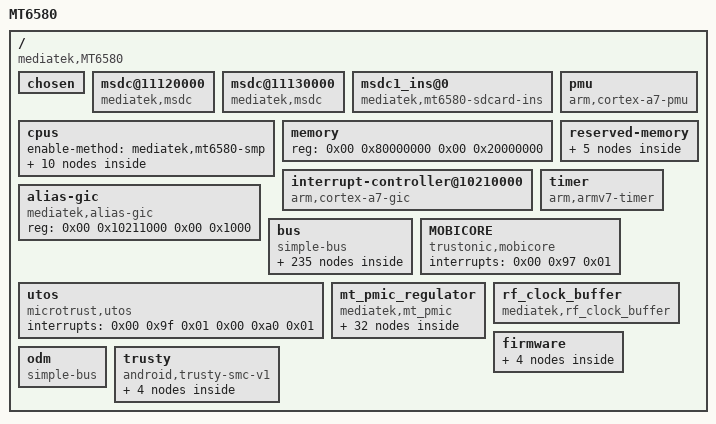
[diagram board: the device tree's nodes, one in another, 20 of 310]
/dts-v1/;

/ {
	model = "MT6580";
	compatible = "mediatek,MT6580";
	interrupt-parent = <0x01>;
	#address-cells = <0x02>;
	#size-cells = <0x02>;

	chosen {
		bootargs = "console=tty0 console=ttyMT3,921600n1 vmalloc=496M androidboot.hardware=mt6580 firmware_class.path=/vendor/firmware loop.max_part=7";
		linux,phandle = <0x2f>;
		phandle = <0x2f>;
	};

	msdc@11120000 {
		compatible = "mediatek,msdc";
		reg = <0x00 0x11120000 0x00 0x10000>;
		interrupts = <0x00 0x26 0x08>;
		index = [00];
		clk_src = [02];
		bus-width = <0x08>;
		max-frequency = <0xbebc200>;
		cap-mmc-highspeed;
		mmc-ddr-1_8v;
		mmc-hs200-1_8v;
		no-sd;
		no-sdio;
		non-removable;
		pinctl = <0x02>;
		pinctl_hs200 = <0x03>;
		register_setting = <0x04>;
		host_function = [00];
		bootable;
		status = "okay";
		vmmc-supply = <0x05>;
		linux,phandle = <0x30>;
		phandle = <0x30>;
	};

	msdc@11130000 {
		compatible = "mediatek,msdc";
		reg = <0x00 0x11130000 0x00 0x10000>;
		interrupts = <0x00 0x27 0x08>;
		index = [01];
		clk_src = [02];
		bus-width = <0x04>;
		max-frequency = <0xbebc200>;
		cap-sd-highspeed;
		sd-uhs-sdr12;
		sd-uhs-sdr25;
		sd-uhs-ddr50;
		no-mmc;
		no-sdio;
		pinctrl-names = "default\0insert_cfg";
		pinctrl-0 = <0x06>;
		pinctrl-1 = <0x07>;
		pinctl = <0x08>;
		pinctl_sdr104 = <0x09>;
		pinctl_sdr50 = <0x0a>;
		pinctl_ddr50 = <0x0b>;
		register_setting = <0x0c>;
		host_function = [01];
		cd_level = [01];
		cd-gpios = <0x0d 0x03 0x00>;
		status = "okay";
		vmmc-supply = <0x0e>;
		vqmmc-supply = <0x0f>;
		linux,phandle = <0x31>;
		phandle = <0x31>;
	};

	msdc1_ins@0 {
		compatible = "mediatek,mt6580-sdcard-ins";
		linux,phandle = <0x32>;
		phandle = <0x32>;
	};

	cpus {
		#address-cells = <0x01>;
		#size-cells = <0x00>;
		enable-method = "mediatek,mt6580-smp";

		cpu@0 {
			device_type = "cpu";
			compatible = "arm,cortex-a7";
			reg = <0x00>;
			clock-frequency = <0x6553f100>;
			linux,phandle = <0x10>;
			phandle = <0x10>;
		};

		cpu@1 {
			device_type = "cpu";
			compatible = "arm,cortex-a7";
			reg = <0x01>;
			clock-frequency = <0x6553f100>;
			linux,phandle = <0x11>;
			phandle = <0x11>;
		};

		cpu@2 {
			device_type = "cpu";
			compatible = "arm,cortex-a7";
			reg = <0x02>;
			clock-frequency = <0x6553f100>;
			linux,phandle = <0x12>;
			phandle = <0x12>;
		};

		cpu@3 {
			device_type = "cpu";
			compatible = "arm,cortex-a7";
			reg = <0x03>;
			clock-frequency = <0x6553f100>;
			linux,phandle = <0x13>;
			phandle = <0x13>;
		};

		cpu-map {

			cluster0 {

				core0 {
					cpu = <0x10>;
				};

				core1 {
					cpu = <0x11>;
				};

				core2 {
					cpu = <0x12>;
				};

				core3 {
					cpu = <0x13>;
				};
			};
		};
	};

	pmu {
		compatible = "arm,cortex-a7-pmu";
		interrupts = <0x00 0x04 0x08 0x00 0x05 0x08 0x00 0x06 0x08 0x00 0x07 0x08>;
	};

	memory {
		device_type = "memory";
		reg = <0x00 0x80000000 0x00 0x20000000>;
	};

	reserved-memory {
		#address-cells = <0x02>;
		#size-cells = <0x02>;
		ranges;
		linux,phandle = <0x33>;
		phandle = <0x33>;

		consys-reserve-memory {
			compatible = "mediatek,consys-reserve-memory";
			no-map;
			size = <0x00 0x200000>;
			alignment = <0x00 0x200000>;
		};

		reserve-memory-ccci_md1 {
			compatible = "mediatek,reserve-memory-ccci_md1";
			no-map;
			size = <0x00 0x1800000>;
			alignment = <0x00 0x2000000>;
			alloc-ranges = <0x00 0x80000000 0x00 0x80000000>;
		};

		pstore-reserved-memory@83f10000 {
			compatible = "mediatek,pstore";
			reg = <0x00 0x83f10000 0x00 0xe0000>;
		};

		ram_console-reserved-memory@83f00000 {
			compatible = "mediatek,ram_console";
			reg = <0x00 0x83f00000 0x00 0x10000>;
		};

		minirdump-reserved-memory@83ff0000 {
			compatible = "mediatek, minirdump";
			reg = <0x00 0x83ff0000 0x00 0x10000>;
		};
	};

	interrupt-controller@10210000 {
		compatible = "arm,cortex-a7-gic";
		#interrupt-cells = <0x03>;
		#address-cells = <0x00>;
		interrupt-controller;
		reg = <0x00 0x10211000 0x00 0x1000 0x00 0x10212000 0x00 0x1000 0x00 0x10200100 0x00 0x1000>;
		interrupts = <0x01 0x09 0xf04>;
		linux,phandle = <0x01>;
		phandle = <0x01>;
	};

	alias-gic {
		compatible = "mediatek,alias-gic";
		reg = <0x00 0x10211000 0x00 0x1000>;
	};

	timer {
		compatible = "arm,armv7-timer";
		interrupts = <0x01 0x0d 0x08 0x01 0x0e 0x08 0x01 0x0b 0x08 0x01 0x0a 0x08>;
		clock-frequency = <0xc65d40>;
	};

	bus {
		compatible = "simple-bus";
		#address-cells = <0x01>;
		#size-cells = <0x01>;
		ranges = <0x00 0x00 0x00 0xffffffff>;
		linux,phandle = <0x34>;
		phandle = <0x34>;

		chipid@08000000 {
			compatible = "mediatek,chipid";
			reg = <0x8000000 0x04 0x8000004 0x04 0x8000008 0x04 0x800000c 0x04>;
		};

		TOPCKGEN@0x10000000 {
			compatible = "mediatek,TOPCKGEN";
			reg = <0x10000000 0x1000>;
		};

		INFRACFG_AO@0x10001000 {
			compatible = "mediatek,INFRACFG_AO";
			reg = <0x10001000 0x1000>;
		};

		bat_meter {
			compatible = "mediatek,bat_meter";
			r_bat_sense = <0x04>;
			r_i_sense = <0x04>;
			r_charger_1 = <0x14a>;
			r_charger_2 = <0x27>;
			temperature_t0 = <0x6e>;
			temperature_t1 = <0x00>;
			temperature_t2 = <0x19>;
			temperature_t3 = <0x32>;
			temperature_t = <0xff>;
			fg_meter_resistance = <0x00>;
			q_max_pos_50 = <0xdd7>;
			q_max_pos_25 = <0xe11>;
			q_max_pos_0 = <0xe07>;
			q_max_neg_10 = <0xd86>;
			q_max_pos_50_h_current = <0xdbd>;
			q_max_pos_25_h_current = <0xde3>;
			q_max_pos_0_h_current = <0x968>;
			q_max_neg_10_h_current = <0x51f>;
			oam_d5 = <0x00>;
			change_tracking_point = <0x01>;
			cust_tracking_point = <0x00>;
			cust_r_sense = <0xc8>;
			cust_hw_cc = <0x00>;
			aging_tuning_value = <0x67>;
			cust_r_fg_offset = <0x00>;
			ocv_board_compesate = <0x00>;
			r_fg_board_base = <0x3e8>;
			r_fg_board_slope = <0x3e8>;
			car_tune_value = <0x64>;
			current_detect_r_fg = <0x0a>;
			minerroroffset = <0x3e8>;
			fg_vbat_average_size = <0x12>;
			r_fg_value = <0x0a>;
			cust_poweron_delta_capacity_tolrance = <0x3c>;
			cust_poweron_low_capacity_tolrance = <0x05>;
			cust_poweron_max_vbat_tolrance = <0x5a>;
			cust_poweron_delta_vbat_tolrance = <0x1e>;
			cust_poweron_delta_hw_sw_ocv_capacity_tolrance = <0x0a>;
			fixed_tbat_25 = <0x00>;
			vbat_normal_wakeup = <0xe10>;
			vbat_low_power_wakeup = <0xdac>;
			normal_wakeup_period = <0x1518>;
			low_power_wakeup_period = <0x12c>;
			close_poweroff_wakeup_period = <0x1e>;
			vbat_remove_detection = <0x00>;
			rbat_pull_up_r = <0x4204>;
			rbat_pull_up_volt = <0x708>;
			batt_temperature_table_num = <0x11>;
			batt_temperature_table = <0xffffffec 0x10a8d 0xfffffff1 0xd192 0xfffffff6 0xa60a 0xfffffffb 0x8464 0x00 0x6a53 0x05 0x5605 0x0a 0x4606 0x0f 0x3952 0x14 0x2f31 0x19 0x2710 0x1e 0x207b 0x23 0x1b24 0x28 0x16ca 0x2d 0x1335 0x32 0x1041 0x37 0xdcf 0x3c 0xbc6>;
			battery_profile_t0_num = <0x44>;
			battery_profile_t0 = <0x00 0x1125 0x02 0x110c 0x03 0x10f6 0x05 0x10df 0x06 0x10ca 0x08 0x10b6 0x09 0x10a3 0x0b 0x1091 0x0d 0x107f 0x0e 0x106e 0x10 0x105d 0x11 0x104c 0x13 0x103b 0x14 0x102a 0x16 0x1019 0x17 0x1008 0x19 0xff9 0x1b 0xfea 0x1c 0xfd9 0x1e 0xfc4 0x1f 0xfaa 0x21 0xf93 0x22 0xf80 0x24 0xf71 0x26 0xf64 0x27 0xf59 0x29 0xf4d 0x2a 0xf43 0x2c 0xf38 0x2d 0xf2e 0x2f 0xf24 0x30 0xf19 0x32 0xf10 0x34 0xf08 0x35 0xf00 0x37 0xef8 0x38 0xef1 0x3a 0xeea 0x3b 0xee4 0x3d 0xede 0x3f 0xed9 0x40 0xed5 0x42 0xed1 0x43 0xecd 0x45 0xeca 0x46 0xec7 0x48 0xec4 0x49 0xec0 0x4b 0xebc 0x4d 0xeb8 0x4e 0xeb4 0x50 0xeaf 0x51 0xeaa 0x53 0xea4 0x54 0xe9d 0x56 0xe95 0x58 0xe8d 0x59 0xe84 0x5b 0xe7d 0x5c 0xe77 0x5e 0xe71 0x5f 0xe6b 0x61 0xe5e 0x62 0xe39 0x64 0xdf3 0x64 0xdf3 0x64 0xdf3 0x64 0xdf3>;
			battery_profile_t1_num = <0x44>;
			battery_profile_t1 = <0x00 0x1125 0x02 0x110a 0x03 0x10f4 0x05 0x10e0 0x06 0x10cd 0x08 0x10b9 0x09 0x10a7 0x0b 0x1096 0x0c 0x1084 0x0e 0x1073 0x0f 0x1062 0x11 0x1051 0x12 0x1041 0x14 0x1031 0x15 0x1020 0x17 0x1010 0x18 0x1001 0x1a 0xff4 0x1b 0xfe7 0x1d 0xfd7 0x1e 0xfc0 0x20 0xfa8 0x21 0xf94 0x23 0xf85 0x24 0xf78 0x26 0xf6c 0x27 0xf60 0x29 0xf54 0x2a 0xf46 0x2c 0xf3a 0x2d 0xf2e 0x2f 0xf23 0x30 0xf19 0x32 0xf0f 0x33 0xf06 0x35 0xeff 0x36 0xef7 0x38 0xef0 0x39 0xeea 0x3b 0xee5 0x3c 0xede 0x3e 0xeda 0x3f 0xed5 0x41 0xed1 0x42 0xecd 0x44 0xecb 0x45 0xec8 0x47 0xec5 0x48 0xec3 0x4a 0xec0 0x4b 0xebc 0x4d 0xeb9 0x4e 0xeb4 0x50 0xeaf 0x51 0xea9 0x53 0xea1 0x54 0xe99 0x56 0xe90 0x57 0xe86 0x59 0xe7b 0x5a 0xe73 0x5c 0xe6f 0x5d 0xe6b 0x5f 0xe64 0x60 0xe47 0x62 0xdf9 0x63 0xd80 0x64 0xce5>;
			battery_profile_t2_num = <0x44>;
			battery_profile_t2 = <0x00 0x1125 0x02 0x110c 0x03 0x10f9 0x05 0x10e7 0x06 0x10d4 0x08 0x10c2 0x09 0x10b0 0x0b 0x109f 0x0c 0x108d 0x0e 0x107b 0x0f 0x106b 0x11 0x1059 0x12 0x1049 0x14 0x1038 0x15 0x1027 0x17 0x1017 0x18 0x1007 0x1a 0xff6 0x1b 0xfe7 0x1d 0xfdb 0x1e 0xfcc 0x20 0xfb8 0x21 0xfa7 0x23 0xf9a 0x24 0xf92 0x26 0xf86 0x27 0xf7a 0x29 0xf6d 0x2a 0xf5f 0x2c 0xf4f 0x2d 0xf3c 0x2f 0xf2d 0x30 0xf21 0x32 0xf17 0x33 0xf0e 0x35 0xf05 0x36 0xeff 0x38 0xef7 0x39 0xef1 0x3b 0xeea 0x3c 0xee5 0x3e 0xee0 0x3f 0xeda 0x41 0xed6 0x42 0xed2 0x44 0xecd 0x45 0xec9 0x47 0xec6 0x48 0xec1 0x4a 0xebb 0x4b 0xeb6 0x4d 0xeb1 0x4e 0xeaa 0x50 0xea4 0x51 0xe9f 0x53 0xe9a 0x54 0xe92 0x56 0xe88 0x57 0xe80 0x59 0xe74 0x5a 0xe6c 0x5c 0xe6a 0x5d 0xe69 0x5f 0xe66 0x60 0xe54 0x62 0xe14 0x63 0xdb0 0x64 0xcf7>;
			battery_profile_t3_num = <0x44>;
			battery_profile_t3 = <0x00 0x1113 0x02 0x10fe 0x03 0x10ea 0x05 0x10d8 0x06 0x10c7 0x08 0x10b4 0x09 0x10a3 0x0b 0x1092 0x0c 0x1080 0x0e 0x106f 0x0f 0x105e 0x11 0x104c 0x12 0x103c 0x14 0x102b 0x15 0x101b 0x17 0x100b 0x18 0xffb 0x1a 0xfeb 0x1b 0xfdc 0x1d 0xfcd 0x1f 0xfbf 0x20 0xfb1 0x22 0xfa4 0x23 0xf96 0x25 0xf8a 0x26 0xf7d 0x28 0xf71 0x29 0xf66 0x2b 0xf58 0x2c 0xf45 0x2e 0xf32 0x2f 0xf25 0x31 0xf1a 0x32 0xf10 0x34 0xf07 0x35 0xf00 0x37 0xef9 0x38 0xef2 0x3a 0xeeb 0x3c 0xee5 0x3d 0xee0 0x3f 0xeda 0x40 0xed5 0x42 0xed0 0x43 0xecc 0x45 0xec8 0x46 0xec3 0x48 0xebd 0x49 0xeb1 0x4b 0xea9 0x4c 0xea2 0x4e 0xe9c 0x4f 0xe95 0x51 0xe90 0x52 0xe8b 0x54 0xe83 0x56 0xe7a 0x57 0xe71 0x59 0xe66 0x5a 0xe5f 0x5c 0xe5e 0x5d 0xe5c 0x5f 0xe59 0x60 0xe43 0x62 0xe01 0x63 0xd9f 0x64 0xceb 0x64 0xc07>;
			r_profile_t0_num = <0x44>;
			r_profile_t0 = <0x514 0x1125 0x514 0x110c 0x4e9 0x10f6 0x4b5 0x10df 0x48a 0x10ca 0x463 0x10b6 0x440 0x10a3 0x423 0x1091 0x40b 0x107f 0x3f3 0x106e 0x3e0 0x105d 0x3d1 0x104c 0x3c4 0x103b 0x3b8 0x102a 0x3ab 0x1019 0x3a3 0x1008 0x39b 0xff9 0x399 0xfea 0x392 0xfd9 0x389 0xfc4 0x37f 0xfaa 0x379 0xf93 0x374 0xf80 0x37a 0xf71 0x37f 0xf64 0x382 0xf59 0x388 0xf4d 0x38d 0xf43 0x38c 0xf38 0x38e 0xf2e 0x38f 0xf24 0x392 0xf19 0x396 0xf10 0x399 0xf08 0x39c 0xf00 0x3a0 0xef8 0x3a1 0xef1 0x3a2 0xeea 0x3a6 0xee4 0x3a9 0xede 0x3ad 0xed9 0x3b2 0xed5 0x3b7 0xed1 0x3bd 0xecd 0x3c3 0xeca 0x3c9 0xec7 0x3d2 0xec4 0x3dc 0xec0 0x3e8 0xebc 0x3f4 0xeb8 0x3ff 0xeb4 0x40b 0xeaf 0x41a 0xeaa 0x426 0xea4 0x436 0xe9d 0x449 0xe95 0x459 0xe8d 0x46c 0xe84 0x485 0xe7d 0x49f 0xe77 0x4c3 0xe71 0x4f2 0xe6b 0x529 0xe5e 0x566 0xe39 0x7e4 0xdf3 0x7e4 0xdf3 0x7e4 0xdf3 0x7e4 0xdf3>;
			r_profile_t1_num = <0x44>;
			r_profile_t1 = <0x357 0x1125 0x357 0x110a 0x34b 0x10f4 0x33f 0x10e0 0x331 0x10cd 0x326 0x10b9 0x31b 0x10a7 0x30e 0x1096 0x301 0x1084 0x2f4 0x1073 0x2ea 0x1062 0x2df 0x1051 0x2d5 0x1041 0x2cd 0x1031 0x2c3 0x1020 0x2bc 0x1010 0x2b2 0x1001 0x2af 0xff4 0x2ac 0xfe7 0x2a5 0xfd7 0x297 0xfc0 0x28c 0xfa8 0x287 0xf94 0x286 0xf85 0x285 0xf78 0x284 0xf6c 0x281 0xf60 0x27c 0xf54 0x277 0xf46 0x274 0xf3a 0x270 0xf2e 0x26f 0xf23 0x270 0xf19 0x270 0xf0f 0x270 0xf06 0x271 0xeff 0x271 0xef7 0x272 0xef0 0x276 0xeea 0x279 0xee5 0x27e 0xede 0x284 0xeda 0x284 0xed5 0x284 0xed1 0x285 0xecd 0x288 0xecb 0x28c 0xec8 0x291 0xec5 0x29b 0xec3 0x2a4 0xec0 0x2ae 0xebc 0x2bb 0xeb9 0x2c8 0xeb4 0x2d6 0xeaf 0x2e7 0xea9 0x2fb 0xea1 0x311 0xe99 0x32a 0xe90 0x346 0xe86 0x365 0xe7b 0x387 0xe73 0x3b2 0xe6f 0x3e5 0xe6b 0x420 0xe64 0x456 0xe47 0x48d 0xdf9 0x447 0xd80 0x2d2 0xce5>;
			r_profile_t2_num = <0x44>;
			r_profile_t2 = <0xb8 0x1125 0xb8 0x110c 0xb8 0x10f9 0xba 0x10e7 0xba 0x10d4 0xb9 0x10c2 0xb7 0x10b0 0xb7 0x109f 0xb7 0x108d 0xb9 0x107b 0xb8 0x106b 0xb6 0x1059 0xb7 0x1049 0xb8 0x1038 0xb6 0x1027 0xb8 0x1017 0xb9 0x1007 0xb8 0xff6 0xbb 0xfe7 0xc1 0xfdb 0xc1 0xfcc 0xc0 0xfb8 0xc0 0xfa7 0xbe 0xf9a 0xca 0xf92 0xc7 0xf86 0xc6 0xf7a 0xc2 0xf6d 0xc3 0xf5f 0xbf 0xf4f 0xb3 0xf3c 0xad 0xf2d 0xa9 0xf21 0xa6 0xf17 0xaa 0xf0e 0xab 0xf05 0xab 0xeff 0xa8 0xef7 0xaa 0xef1 0xab 0xeea 0xaf 0xee5 0xb0 0xee0 0xaf 0xeda 0xb1 0xed6 0xb2 0xed2 0xb4 0xecd 0xb6 0xec9 0xb5 0xec6 0xb8 0xec1 0xb4 0xebb 0xb3 0xeb6 0xb4 0xeb1 0xb1 0xeaa 0xb2 0xea4 0xb1 0xe9f 0xb4 0xe9a 0xb5 0xe92 0xb6 0xe88 0xb7 0xe80 0xb9 0xe74 0xb8 0xe6c 0xbc 0xe6a 0xc2 0xe69 0xcd 0xe66 0xd4 0xe54 0xd3 0xe14 0xe3 0xdb0 0x111 0xcf7>;
			r_profile_t3_num = <0x44>;
			r_profile_t3 = <0x80 0x1113 0x80 0x10fe 0x7e 0x10ea 0x7f 0x10d8 0x7f 0x10c7 0x7d 0x10b4 0x7f 0x10a3 0x7f 0x1092 0x7e 0x1080 0x7f 0x106f 0x80 0x105e 0x7f 0x104c 0x7f 0x103c 0x81 0x102b 0x81 0x101b 0x81 0x100b 0x83 0xffb 0x83 0xfeb 0x83 0xfdc 0x85 0xfcd 0x86 0xfbf 0x86 0xfb1 0x88 0xfa4 0x89 0xf96 0x8d 0xf8a 0x8e 0xf7d 0x90 0xf71 0x94 0xf66 0x94 0xf58 0x8a 0xf45 0x81 0xf32 0x80 0xf25 0x7e 0xf1a 0x7d 0xf10 0x7c 0xf07 0x7d 0xf00 0x7d 0xef9 0x7e 0xef2 0x7f 0xeeb 0x80 0xee5 0x81 0xee0 0x81 0xeda 0x82 0xed5 0x83 0xed0 0x84 0xecc 0x85 0xec8 0x87 0xec3 0x85 0xebd 0x7e 0xeb1 0x7d 0xea9 0x7e 0xea2 0x7d 0xe9c 0x7d 0xe95 0x7d 0xe90 0x7f 0xe8b 0x80 0xe83 0x7f 0xe7a 0x80 0xe71 0x7f 0xe66 0x7c 0xe5f 0x7f 0xe5e 0x83 0xe5c 0x8c 0xe59 0x88 0xe43 0x85 0xe01 0x8f 0xd9f 0xab 0xceb 0x188 0xc07>;
		};

		bat_meter1 {
			compatible = "mediatek,bat_meter1";
			r_bat_sense = <0x04>;
			r_i_sense = <0x04>;
			r_charger_1 = <0x14a>;
			r_charger_2 = <0x27>;
			temperature_t0 = <0x6e>;
			temperature_t1 = <0x00>;
			temperature_t2 = <0x19>;
			temperature_t3 = <0x32>;
			temperature_t = <0xff>;
			fg_meter_resistance = <0x00>;
			q_max_pos_50 = <0xd87>;
			q_max_pos_25 = <0xdbb>;
			q_max_pos_0 = <0xdab>;
			q_max_neg_10 = <0xd94>;
			q_max_pos_50_h_current = <0xd6b>;
			q_max_pos_25_h_current = <0xd7c>;
			q_max_pos_0_h_current = <0x99d>;
			q_max_neg_10_h_current = <0x55a>;
			oam_d5 = <0x00>;
			change_tracking_point = <0x01>;
			cust_tracking_point = <0x00>;
			cust_r_sense = <0xc8>;
			cust_hw_cc = <0x00>;
			aging_tuning_value = <0x67>;
			cust_r_fg_offset = <0x00>;
			ocv_board_compesate = <0x00>;
			r_fg_board_base = <0x3e8>;
			r_fg_board_slope = <0x3e8>;
			car_tune_value = <0x64>;
			current_detect_r_fg = <0x0a>;
			minerroroffset = <0x3e8>;
			fg_vbat_average_size = <0x12>;
			r_fg_value = <0x0a>;
			cust_poweron_delta_capacity_tolrance = <0x3c>;
			cust_poweron_low_capacity_tolrance = <0x05>;
			cust_poweron_max_vbat_tolrance = <0x5a>;
			cust_poweron_delta_vbat_tolrance = <0x1e>;
			cust_poweron_delta_hw_sw_ocv_capacity_tolrance = <0x0a>;
			fixed_tbat_25 = <0x00>;
			vbat_normal_wakeup = <0xe10>;
			vbat_low_power_wakeup = <0xdac>;
			normal_wakeup_period = <0x1518>;
			low_power_wakeup_period = <0x12c>;
			close_poweroff_wakeup_period = <0x1e>;
			vbat_remove_detection = <0x00>;
			rbat_pull_up_r = <0x4204>;
			rbat_pull_up_volt = <0x708>;
			batt_temperature_table_num = <0x11>;
			batt_temperature_table = <0xffffffec 0x10a8d 0xfffffff1 0xd192 0xfffffff6 0xa60a 0xfffffffb 0x8464 0x00 0x6a53 0x05 0x5605 0x0a 0x4606 0x0f 0x3952 0x14 0x2f31 0x19 0x2710 0x1e 0x207b 0x23 0x1b24 0x28 0x16ca 0x2d 0x1335 0x32 0x1041 0x37 0xdcf 0x3c 0xbc6>;
			battery_profile_t0_num = <0x64>;
			battery_profile_t0 = <0x00 0x1121 0x02 0x10f8 0x03 0x10d8 0x05 0x10bc 0x06 0x10a4 0x08 0x108d 0x09 0x1079 0x0b 0x1066 0x0c 0x1054 0x0e 0x1042 0x10 0x1031 0x11 0x1020 0x13 0x1010 0x14 0x1002 0x16 0xff2 0x17 0xfe0 0x19 0xfcc 0x1a 0xfb8 0x1c 0xfa5 0x1e 0xf94 0x1f 0xf85 0x21 0xf77 0x22 0xf6a 0x24 0xf5d 0x25 0xf51 0x27 0xf44 0x28 0xf38 0x2a 0xf2d 0x2b 0xf22 0x2d 0xf18 0x2f 0xf0f 0x30 0xf06 0x32 0xefe 0x33 0xef6 0x35 0xeef 0x36 0xee8 0x38 0xee3 0x39 0xede 0x3b 0xeda 0x3d 0xed6 0x3e 0xed2 0x40 0xecf 0x41 0xecc 0x43 0xec9 0x44 0xec6 0x46 0xec2 0x47 0xebf 0x49 0xebb 0x4b 0xeb8 0x4c 0xeb4 0x4e 0xeaf 0x4f 0xeaa 0x51 0xea5 0x52 0xe9f 0x54 0xe98 0x55 0xe91 0x57 0xe89 0x59 0xe80 0x5a 0xe78 0x5c 0xe71 0x5d 0xe6b 0x5f 0xe64 0x60 0xe5c 0x61 0xe55 0x62 0xe4c 0x62 0xe42 0x62 0xe35 0x63 0xe29 0x63 0xe1c 0x63 0xe10 0x64 0xe04 0x64 0xdf8 0x64 0xded 0x64 0xde3 0x64 0xdd9 0x64 0xdce 0x64 0xdc4 0x64 0xdbb 0x64 0xdb2 0x64 0xdaa 0x64 0xda1 0x64 0xd9a 0x64 0xd92 0x64 0xd8b 0x64 0xd84 0x64 0xd7d 0x64 0xd77 0x64 0xd70 0x64 0xd6a 0x64 0xd65 0x64 0xd5f 0x64 0xd5a 0x64 0xd54 0x64 0xd50 0x64 0xd4c 0x64 0xd48 0x64 0xd48 0x64 0xd48 0x64 0xd48 0x64 0xd48>;
			battery_profile_t1_num = <0x4a>;
			battery_profile_t1 = <0x00 0x1119 0x02 0x10f9 0x03 0x10e0 0x05 0x10c9 0x06 0x10b4 0x08 0x10a0 0x09 0x108d 0x0b 0x107b 0x0c 0x1069 0x0e 0x1058 0x0f 0x1046 0x11 0x1035 0x13 0x1024 0x14 0x1014 0x16 0x1004 0x17 0xff6 0x19 0xfe7 0x1a 0xfd6 0x1c 0xfc2 0x1d 0xfad 0x1f 0xf9b 0x20 0xf8c 0x22 0xf7e 0x23 0xf71 0x25 0xf65 0x27 0xf58 0x28 0xf4b 0x2a 0xf3d 0x2b 0xf30 0x2d 0xf24 0x2e 0xf19 0x30 0xf0f 0x31 0xf06 0x33 0xefe 0x34 0xef6 0x36 0xeef 0x38 0xee9 0x39 0xee3 0x3b 0xedd 0x3c 0xed8 0x3e 0xed4 0x3f 0xed1 0x41 0xece 0x42 0xecc 0x44 0xec9 0x45 0xec6 0x47 0xec3 0x49 0xec0 0x4a 0xebd 0x4c 0xeb9 0x4d 0xeb4 0x4f 0xeaf 0x50 0xea9 0x52 0xea2 0x53 0xe9b 0x55 0xe92 0x56 0xe88 0x58 0xe7e 0x59 0xe74 0x5b 0xe6e 0x5d 0xe69 0x5e 0xe64 0x60 0xe54 0x61 0xe20 0x62 0xde2 0x63 0xdba 0x63 0xd97 0x64 0xd77 0x64 0xd57 0x64 0xd48 0x64 0xd48 0x64 0xd48 0x64 0xd48 0x64 0xd48>;
			battery_profile_t2_num = <0x46>;
			battery_profile_t2 = <0x00 0x111f 0x02 0x1107 0x03 0x10f4 0x05 0x10e1 0x06 0x10ce 0x08 0x10bc 0x09 0x10aa 0x0b 0x1097 0x0c 0x1085 0x0e 0x1073 0x0f 0x1062 0x11 0x1050 0x12 0x103f 0x14 0x102e 0x16 0x101d 0x17 0x100c 0x19 0xffc 0x1a 0xfed 0x1c 0xfde 0x1d 0xfcf 0x1f 0xfbe 0x20 0xfae 0x22 0xfa0 0x23 0xf94 0x25 0xf88 0x26 0xf7c 0x28 0xf6f 0x29 0xf60 0x2b 0xf4e 0x2d 0xf3d 0x2e 0xf2e 0x30 0xf21 0x31 0xf17 0x33 0xf0e 0x34 0xf06 0x36 0xefe 0x37 0xef7 0x39 0xef0 0x3a 0xeea 0x3c 0xee4 0x3d 0xedf 0x3f 0xeda 0x41 0xed5 0x42 0xed1 0x44 0xecd 0x45 0xec9 0x47 0xec4 0x48 0xec0 0x4a 0xeba 0x4b 0xeb4 0x4d 0xeae 0x4e 0xea8 0x50 0xea3 0x51 0xe9e 0x53 0xe97 0x54 0xe8e 0x56 0xe86 0x58 0xe7c 0x59 0xe70 0x5b 0xe6b 0x5c 0xe69 0x5e 0xe66 0x5f 0xe5f 0x61 0xe37 0x62 0xde7 0x64 0xd67 0x64 0xd48 0x64 0xd48 0x64 0xd48 0x64 0xd48>;
			battery_profile_t3_num = <0x45>;
			battery_profile_t3 = <0x00 0x110c 0x02 0x10f5 0x03 0x10e0 0x05 0x10cd 0x06 0x10ba 0x08 0x10a8 0x09 0x1095 0x0b 0x1083 0x0c 0x1072 0x0e 0x1060 0x10 0x104e 0x11 0x103d 0x13 0x102c 0x14 0x101c 0x16 0x100b 0x17 0xffb 0x19 0xfeb 0x1b 0xfdc 0x1c 0xfcd 0x1e 0xfbf 0x1f 0xfb0 0x21 0xfa3 0x22 0xf96 0x24 0xf89 0x25 0xf7d 0x27 0xf71 0x29 0xf65 0x2a 0xf57 0x2c 0xf45 0x2d 0xf32 0x2f 0xf24 0x30 0xf1a 0x32 0xf10 0x33 0xf08 0x35 0xf00 0x37 0xef8 0x38 0xef2 0x3a 0xeeb 0x3b 0xee5 0x3d 0xedf 0x3e 0xeda 0x40 0xed5 0x41 0xed1 0x43 0xecd 0x45 0xec9 0x46 0xec4 0x48 0xebd 0x49 0xeb1 0x4b 0xea9 0x4c 0xea3 0x4e 0xe9c 0x50 0xe96 0x51 0xe91 0x53 0xe8b 0x54 0xe83 0x56 0xe7a 0x57 0xe71 0x59 0xe65 0x5a 0xe60 0x5c 0xe5f 0x5e 0xe5d 0x5f 0xe56 0x61 0xe2e 0x62 0xde2 0x64 0xd6b 0x64 0xd48 0x64 0xd48 0x64 0xd48 0x64 0xd48>;
			r_profile_t0_num = <0x63>;
			r_profile_t0 = <0x512 0x10f8 0x4df 0x10d8 0x4a8 0x10bc 0x47b 0x10a4 0x453 0x108d 0x433 0x1079 0x417 0x1066 0x3ff 0x1054 0x3ea 0x1042 0x3d7 0x1031 0x3c5 0x1020 0x3b1 0x1010 0x3a9 0x1002 0x39d 0xff2 0x390 0xfe0 0x386 0xfcc 0x373 0xfb8 0x364 0xfa5 0x357 0xf94 0x355 0xf85 0x34f 0xf77 0x350 0xf6a 0x34d 0xf5d 0x348 0xf51 0x34a 0xf44 0x343 0xf38 0x343 0xf2d 0x33e 0xf22 0x343 0xf18 0x346 0xf0f 0x345 0xf06 0x33b 0xefe 0x340 0xef6 0x348 0xeef 0x345 0xee8 0x348 0xee3 0x354 0xede 0x35c 0xeda 0x35f 0xed6 0x36b 0xed2 0x372 0xecf 0x378 0xecc 0x389 0xec9 0x390 0xec6 0x3a5 0xec2 0x3af 0xebf 0x3c8 0xebb 0x3d9 0xeb8 0x3ed 0xeb4 0x3fe 0xeaf 0x412 0xeaa 0x429 0xea5 0x43b 0xe9f 0x44e 0xe98 0x463 0xe91 0x47e 0xe89 0x492 0xe80 0x4b3 0xe78 0x4ce 0xe71 0x500 0xe6b 0x52f 0xe64 0x561 0xe5c 0x555 0xe55 0x546 0xe4c 0x535 0xe42 0x520 0xe35 0x50c 0xe29 0x4f6 0xe1c 0x4e2 0xe10 0x4ce 0xe04 0x4ba 0xdf8 0x4a8 0xded 0x497 0xde3 0x486 0xdd9 0x476 0xdce 0x465 0xdc4 0x456 0xdbb 0x447 0xdb2 0x438 0xdaa 0x42b 0xda1 0x41d 0xd9a 0x412 0xd92 0x404 0xd8b 0x3fa 0xd84 0x3ef 0xd7d 0x3e3 0xd77 0x3d9 0xd70 0x3cf 0xd6a 0x3c5 0xd65 0x3bb 0xd5f 0x3b4 0xd5a 0x3aa 0xd54 0x3a2 0xd50 0x39b 0xd4c 0x393 0xd48 0x38e 0xd48 0x38e 0xd48 0x38e 0xd48 0x38e 0xd48>;
			r_profile_t1_num = <0x49>;
			r_profile_t1 = <0x305 0x10f9 0x2ff 0x10e0 0x2f3 0x10c9 0x2e9 0x10b4 0x2da 0x10a0 0x2c9 0x108d 0x2a3 0x107b 0x299 0x1069 0x28a 0x1058 0x2a5 0x1046 0x299 0x1035 0x28f 0x1024 0x288 0x1014 0x283 0x1004 0x280 0xff6 0x280 0xfe7 0x279 0xfd6 0x26f 0xfc2 0x25d 0xfad 0x255 0xf9b 0x253 0xf8c 0x256 0xf7e 0x258 0xf71 0x256 0xf65 0x232 0xf58 0x229 0xf4b 0x228 0xf3d 0x242 0xf30 0x23f 0xf24 0x23d 0xf19 0x238 0xf0f 0x23d 0xf06 0x241 0xefe 0x23f 0xef6 0x23f 0xeef 0x242 0xee9 0x249 0xee3 0x249 0xedd 0x247 0xed8 0x249 0xed4 0x24e 0xed1 0x246 0xece 0x24c 0xecc 0x250 0xec9 0x27b 0xec6 0x291 0xec3 0x29e 0xec0 0x2a8 0xebd 0x2b4 0xeb9 0x2c3 0xeb4 0x2d8 0xeaf 0x2f0 0xea9 0x304 0xea2 0x313 0xe9b 0x32a 0xe92 0x348 0xe88 0x372 0xe7e 0x393 0xe74 0x3b6 0xe6e 0x3bd 0xe69 0x3ea 0xe64 0x410 0xe54 0x474 0xe20 0x495 0xde2 0x453 0xdba 0x418 0xd97 0x3e3 0xd77 0x3ae 0xd57 0x3ae 0xd48 0x3ae 0xd48 0x3ae 0xd48 0x3ae 0xd48 0x3ae 0xd48>;
			r_profile_t2_num = <0x45>;
			r_profile_t2 = <0xbc 0x1107 0xbe 0x10f4 0xbe 0x10e1 0xbc 0x10ce 0xbb 0x10bc 0xbb 0x10aa 0xb6 0x1097 0xb6 0x1085 0xb4 0x1073 0xb6 0x1062 0xb4 0x1050 0xb4 0x103f 0xb2 0x102e 0xb2 0x101d 0xb1 0x100c 0xb4 0xffc 0xb6 0xfed 0xb4 0xfde 0xb4 0xfcf 0xb2 0xfbe 0xb4 0xfae 0xb6 0xfa0 0xb9 0xf94 0xb9 0xf88 0xbb 0xf7c 0xbb 0xf6f 0xb7 0xf60 0xaf 0xf4e 0xa7 0xf3d 0xa0 0xf2e 0x9d 0xf21 0x9e 0xf17 0x9e 0xf0e 0xa0 0xf06 0x9e 0xefe 0xa0 0xef7 0xa0 0xef0 0xa2 0xeea 0xa3 0xee4 0xa5 0xedf 0xa5 0xeda 0xa7 0xed5 0xa8 0xed1 0xaa 0xecd 0xaa 0xec9 0xa8 0xec4 0xaa 0xec0 0xa7 0xeba 0xa5 0xeb4 0xa5 0xeae 0xa5 0xea8 0xa8 0xea3 0xac 0xe9e 0xad 0xe97 0xaf 0xe8e 0xb4 0xe86 0xb9 0xe7c 0xbc 0xe70 0xc3 0xe6b 0xcd 0xe69 0xdc 0xe66 0xee 0xe5f 0xfa 0xe37 0x115 0xde7 0x145 0xd67 0x145 0xd48 0x145 0xd48 0x145 0xd48 0x145 0xd48>;
			r_profile_t3_num = <0x44>;
			r_profile_t3 = <0x71 0x10f5 0x70 0x10e0 0x70 0x10cd 0x70 0x10ba 0x70 0x10a8 0x6e 0x1095 0x70 0x1083 0x70 0x1072 0x70 0x1060 0x70 0x104e 0x70 0x103d 0x70 0x102c 0x71 0x101c 0x71 0x100b 0x73 0xffb 0x73 0xfeb 0x75 0xfdc 0x75 0xfcd 0x76 0xfbf 0x76 0xfb0 0x78 0xfa3 0x7a 0xf96 0x7b 0xf89 0x7f 0xf7d 0x80 0xf71 0x82 0xf65 0x82 0xf57 0x7b 0xf45 0x71 0xf32 0x6e 0xf24 0x70 0xf1a 0x6e 0xf10 0x6e 0xf08 0x6e 0xf00 0x6e 0xef8 0x71 0xef2 0x70 0xeeb 0x71 0xee5 0x71 0xedf 0x73 0xeda 0x75 0xed5 0x76 0xed1 0x78 0xecd 0x7a 0xec9 0x7a 0xec4 0x76 0xebd 0x70 0xeb1 0x70 0xea9 0x71 0xea3 0x71 0xe9c 0x71 0xe96 0x73 0xe91 0x73 0xe8b 0x73 0xe83 0x73 0xe7a 0x73 0xe71 0x70 0xe65 0x70 0xe60 0x75 0xe5f 0x7a 0xe5d 0x80 0xe56 0x7a 0xe2e 0x7f 0xde2 0x8a 0xd6b 0x8a 0xd48 0x8a 0xd48 0x8a 0xd48 0x8a 0xd48>;
		};

		BAT_NOTIFY {
			compatible = "mediatek,bat_notify";
		};

		bat_comm {
			compatible = "mediatek,battery";
			linux,phandle = <0x35>;
			phandle = <0x35>;
		};

		keypad@10002000 {
			compatible = "mediatek,kp";
			reg = <0x10002000 0x1000>;
			interrupts = <0x00 0x6d 0x02>;
			linux,phandle = <0x36>;
			phandle = <0x36>;
		};

		PERICFG@0x10003000 {
			compatible = "mediatek,PERICFG";
			reg = <0x10003000 0x1000>;
		};

		RESERVED@0x10004000 {
			compatible = "mediatek,RESERVED";
			reg = <0x10004000 0x1000>;
		};

		gpio {
			compatible = "mediatek,gpio_usage_mapping";
			linux,phandle = <0x37>;
			phandle = <0x37>;
		};

		gpio@0x10005000 {
			compatible = "mediatek,gpio";
			reg = <0x10005000 0x1000>;
			linux,phandle = <0x38>;
			phandle = <0x38>;
		};

		SLEEP@0x10006000 {
			compatible = "mediatek,SLEEP";
			reg = <0x10006000 0x1000>;
			interrupts = <0x00 0x58 0x08 0x00 0x59 0x08 0x00 0x5a 0x08 0x00 0x5b 0x08>;
		};

		TOPRGU@0x10007000 {
			compatible = "mediatek,TOPRGU";
			reg = <0x10007000 0x1000>;
			interrupts = <0x00 0x9d 0x02>;
		};

		APXGPT@0x10008000 {
			compatible = "mediatek,APXGPT";
			reg = <0x10008000 0x1000>;
			interrupts = <0x00 0x5c 0x08>;
			clock-frequency = <0xc65d40>;
		};

		EFUSEC@0x10009000 {
			compatible = "mediatek,EFUSEC";
			reg = <0x10009000 0x1000>;
		};

		hacc@0x1000A000 {
			compatible = "mediatek,hacc";
			reg = <0x1000a000 0x1000>;
			interrupts = <0x00 0x6e 0x00>;
		};

		cpu_dbgapb@10170000 {
			compatible = "mediatek,hw_dbg";
			num = <0x04>;
			reg = <0x10170000 0x2000 0x10172000 0x2000 0x10174000 0x2000 0x10176000 0x2000>;
			linux,phandle = <0x39>;
			phandle = <0x39>;
		};

		eintc@1000b000 {
			compatible = "mediatek,mt-eic";
			reg = <0x1000b000 0x1000>;
			interrupts = <0x00 0x5e 0x04>;
			#interrupt-cells = <0x02>;
			interrupt-controller;
			mediatek,max_eint_num = <0x1a>;
			mediatek,mapping_table_entry = <0x53>;
			mediatek,mapping_table = <0x00 0x00 0x01 0x01 0x02 0x02 0x03 0x03 0x04 0x04 0x05 0x05 0x06 0x06 0x07 0x07 0x08 0x08 0x09 0x09 0x0a 0x0a 0x0b 0x0b 0x0c 0x0c 0x0d 0x0d 0x0e 0x0e 0x0f 0x0f 0x10 0x00 0x11 0x01 0x12 0x02 0x13 0x03 0x14 0x04 0x15 0x05 0x16 0x06 0x17 0x07 0x18 0x08 0x19 0x09 0x1a 0x0a 0x1b 0x0b 0x1c 0x0c 0x1d 0x0d 0x1e 0x0e 0x1f 0x0f 0x20 0x00 0x21 0x01 0x22 0x02 0x23 0x03 0x24 0x04 0x25 0x05 0x26 0x06 0x27 0x07 0x28 0x08 0x29 0x09 0x2a 0x0a 0x2b 0x0b 0x2c 0x0c 0x2d 0x0d 0x2e 0x0e 0x2f 0x0f 0x30 0x00 0x31 0x01 0x32 0x02 0x33 0x03 0x34 0x03 0x35 0x04 0x36 0x05 0x37 0x06 0x38 0x07 0x39 0x08 0x3a 0x0a 0x3b 0x0b 0x3c 0x0c 0x3d 0x0d 0x3e 0x0e 0x3f 0x0f 0x40 0x00 0x41 0x01 0x42 0x02 0x43 0x03 0x44 0x10 0x45 0x04 0x46 0x05 0x47 0x06 0x48 0x07 0x49 0x08 0x4a 0x09 0x4b 0x0a 0x4c 0x0b 0x4d 0x0c 0x4e 0x0d 0x51 0x00 0x52 0x01 0x53 0x02 0x54 0x03>;
			mediatek,builtin_entry = <0x0b>;
			mediatek,builtin_mapping = <0x00 0x03 0x14 0x01 0x03 0x12 0x07 0x04 0x14 0x08 0x04 0x12 0x09 0x03 0x14 0x0a 0x03 0x12 0x18 0x05 0x14 0x19 0x05 0x12 0x4d 0x02 0x14 0x4e 0x02 0x12 0x0d 0x01 0x11>;
			linux,phandle = <0x14>;
			phandle = <0x14>;

			pmic@13 {
				compatible = "mediatek, pmic-eint";
				interrupt-parent = <0x14>;
				interrupts = <0x0d 0x04>;
				debounce = <0x0d 0x3e8>;
			};
		};

		ap_ccif0@1000C000 {
			compatible = "mediatek,ap_ccif0";
			reg = <0x1000c000 0x1000 0x1000d000 0x1000>;
			interrupts = <0x00 0x5d 0x08 0x00 0x98 0x02>;
			mediatek,ccif_capability = <0x02>;
			mediatek,md_smem_size = <0x200000>;
			linux,phandle = <0x3a>;
			phandle = <0x3a>;
		};

		MCUSYS_CFGREG@0x1020000 {
			compatible = "mediatek,MCUSYS_CFGREG_BASE";
			reg = <0x1020000 0x200>;
		};

		mcucfg@10200000 {
			compatible = "mediatek,mt6580-mcucfg";
			reg = <0x10200000 0x200>;
			linux,phandle = <0x3b>;
			phandle = <0x3b>;
		};

		AES@0x1000E000 {
			compatible = "mediatek,AES";
			reg = <0x1000e000 0x1000>;
		};

		PWRAP@0x1000F000 {
			compatible = "mediatek,PWRAP";
			reg = <0x1000f000 0x1000>;
			interrupts = <0x00 0x6c 0x00>;
		};

		DEVAPC_AO@0x10010000 {
			compatible = "mediatek,DEVAPC_AO";
			reg = <0x10010000 0x1000>;
		};

		MIPI_CONFG@0x10011000 {
			compatible = "mediatek,MIPI_CONFG";
			reg = <0x10011000 0x1000>;
		};

		INFRA_MBIST@0x10012000 {
			compatible = "mediatek,INFRA_MBIST";
			reg = <0x10012000 0x1000>;
		};

		RESERVED@0x10013000 {
			compatible = "mediatek,RESERVED";
			reg = <0x10013000 0x1000>;
		};

		IOCFG_T@0x10014000 {
			compatible = "mediatek,IOCFG_T";
			reg = <0x10014000 0x1000>;
		};

		IOCFG_B@0x10015000 {
			compatible = "mediatek,IOCFG_B";
			reg = <0x10015000 0x1000>;
		};

		IOCFG_L@0x10016000 {
			compatible = "mediatek,IOCFG_L";
			reg = <0x10016000 0x1000>;
		};

		IOCFG_R@0x10017000 {
			compatible = "mediatek,IOCFG_R";
			reg = <0x10017000 0x1000>;
		};

		APMIXED@0x10018000 {
			compatible = "mediatek,APMIXED";
			reg = <0x10018000 0x1000>;
		};

		MCUCFG@0x10200000 {
			compatible = "mediatek,MCUCFG";
			reg = <0x10200000 0x1000>;
		};

		INFRACFG@0x10201000 {
			compatible = "mediatek,INFRACFG";
			reg = <0x10201000 0x1000>;
		};

		sys_cirq@10202000 {
			compatible = "mediatek,mt6580-sys_cirq\0mediatek,mt6735-sys_cirq";
			reg = <0x10202000 0x1000>;
			interrupts = <0x00 0x9e 0x08>;
			mediatek,cirq_num = <0x7e>;
			mediatek,spi_start_offset = <0x20>;
			linux,phandle = <0x3c>;
			phandle = <0x3c>;
		};

		m4u@10203000 {
			cell-index = <0x00>;
			compatible = "mediatek,m4u";
			reg = <0x10203000 0x1000>;
			interrupts = <0x00 0x51 0x08>;
		};

		DEVAPC@0x10204000 {
			compatible = "mediatek,DEVAPC";
			reg = <0x10204000 0x1000>;
			interrupts = <0x00 0x4a 0x08>;
		};

		EMI@0x10205000 {
			compatible = "mediatek,EMI";
			reg = <0x10205000 0x1000>;
			interrupts = <0x00 0x4c 0x04>;
		};

		DRAMC_NAO@0x10206000 {
			compatible = "mediatek,DRAMC_NAO";
			reg = <0x10206000 0x1000>;
		};

		DRAMC0@0x10207000 {
			compatible = "mediatek,DRAMC0";
			reg = <0x10207000 0x1000>;
		};

		DDRPHY@0x10208000 {
			compatible = "mediatek,DDRPHY";
			reg = <0x10208000 0x1000>;
		};

		SRAMROM@0x10209000 {
			compatible = "mediatek,SRAMROM";
			reg = <0x10209000 0x1000>;
		};

		gce@1020a000 {
			compatible = "mediatek,gce";
			reg = <0x1020a000 0x1000>;
			interrupts = <0x00 0x55 0x08 0x00 0x56 0x08>;
			disp_mutex_reg = <0x14015000 0x1000>;
			g3d_config_base = <0x13000000 0x00 0xffff0000>;
			mmsys_config_base = <0x14000000 0x01 0xffff0000>;
			disp_dither_base = <0x14010000 0x02 0xffff0000>;
			mm_na_base = <0x14020000 0x03 0xffff0000>;
			imgsys_base = <0x15000000 0x04 0xffff0000>;
			vdec_gcon_base = <0x16000000 0x05 0xffff0000>;
			venc_gcon_base = <0x17000000 0x06 0xffff0000>;
			conn_peri_base = <0x18000000 0x07 0xffff0000>;
			topckgen_base = <0x10000000 0x08 0xffff0000>;
			kp_base = <0x10010000 0x09 0xffff0000>;
			scp_sram_base = <0x10020000 0x0a 0xffff0000>;
			infra_na3_base = <0x10030000 0x0b 0xffff0000>;
			infra_na4_base = <0x10040000 0x0c 0xffff0000>;
			scp_base = <0x10050000 0x0d 0xffff0000>;
			mcucfg_base = <0x10200000 0x0e 0xffff0000>;
			gcpu_base = <0x10210000 0x0f 0xffff0000>;
			usb0_base = <0x11200000 0x10 0xffff0000>;
			usb_sif_base = <0x11210000 0x11 0xffff0000>;
			audio_base = <0x11220000 0x12 0xffff0000>;
			msdc0_base = <0x11230000 0x13 0xffff0000>;
			msdc1_base = <0x11240000 0x14 0xffff0000>;
			msdc2_base = <0x11250000 0x15 0xffff0000>;
			msdc3_base = <0x11260000 0x16 0xffff0000>;
			pwm_sw_base = <0x1100f000 0x63 0xfffff000>;
			mdp_rdma0_sof = <0x00>;
			mdp_rsz0_sof = <0x01>;
			mdp_rsz1_sof = <0x02>;
			mdp_tdshp_sof = <0x03>;
			mdp_wdma_sof = <0x04>;
			mdp_wrot_sof = <0x05>;
			disp_ovl0_sof = <0x06>;
			disp_rdma0_sof = <0x08>;
			disp_wdma0_sof = <0x0a>;
			disp_color_sof = <0x0c>;
			disp_aal_sof = <0x0d>;
			disp_gamma_sof = <0x0e>;
			disp_dither_sof = <0x0f>;
			disp_pwm0_sof = <0x11>;
			mdp_rdma0_frame_done = <0x12>;
			mdp_rsz0_frame_done = <0x13>;
			mdp_rsz1_frame_done = <0x14>;
			mdp_tdshp_frame_done = <0x15>;
			mdp_wdma_frame_done = <0x16>;
			mdp_wrot_write_frame_done = <0x17>;
			mdp_wrot_read_frame_done = <0x18>;
			disp_ovl0_frame_done = <0x19>;
			disp_rdma0_frame_done = <0x1b>;
			disp_wdma0_frame_done = <0x1d>;
			disp_color_frame_done = <0x1f>;
			disp_aal_frame_done = <0x20>;
			disp_gamma_frame_done = <0x21>;
			disp_dither_frame_done = <0x22>;
			disp_dsi0_frame_done = <0x25>;
			stream_done_0 = <0x26>;
			stream_done_1 = <0x27>;
			stream_done_2 = <0x28>;
			stream_done_3 = <0x29>;
			stream_done_4 = <0x2a>;
			stream_done_5 = <0x2b>;
			stream_done_6 = <0x2c>;
			stream_done_7 = <0x2d>;
			stream_done_8 = <0x2e>;
			stream_done_9 = <0x2f>;
			buf_underrun_event_0 = <0x30>;
			dsi0_te_event = <0x32>;
			isp_frame_done_p2_1 = <0x42>;
			isp_frame_done_p2_0 = <0x43>;
			seninf_cam0_fifo_full = <0x49>;
			apxgpt2_count = <0x10008028>;
		};

		bus_dbg@1020b000 {
			compatible = "mediatek,bus_dbg-v2";
			reg = <0x1020b000 0x1000>;
			interrupts = <0x00 0x49 0x08>;
			two_stage_timeout = <0x01>;
		};

		trng@0x1020f000 {
			compatible = "mediatek,trng";
			reg = <0x1020c000 0x1000 0x10001000 0x1000>;
			interrupts = <0x00 0x57 0x08>;
		};

		MCUCFG_BIU@0x1020D000 {
			compatible = "mediatek,MCUCFG_BIU";
			reg = <0x1020d000 0x1000>;
		};

		DBGSYS_DEM@0x1011A000 {
			compatible = "mediatek,DBGSYS_DEM";
			reg = <0x1011a000 0x1000>;
		};

		DBGSYS_CTI@0x10112000 {
			compatible = "mediatek,DBGSYS_CTI";
			reg = <0x10112000 0x1000>;
		};

		DBGSYS_DAPROM@0x10110000 {
			compatible = "mediatek,DBGSYS_DAPROM";
			reg = <0x10110000 0x1000>;
		};

		DBGSYS_CPU@0x10160000 {
			compatible = "mediatek,DBGSYS_CPU";
			reg = <0x10160000 0x20000>;
		};

		DBGSYS_MDSYS@0x10120000 {
			compatible = "mediatek,DBGSYS_MDSYS";
			reg = <0x10120000 0x10000>;
		};

		dma@0x11000000 {
			compatible = "mediatek,ap_dma";
			reg = <0x11000000 0x1000>;
			interrupts = <0x00 0x30 0x08>;
			linux,phandle = <0x3d>;
			phandle = <0x3d>;
		};

		NFI@0x11001000 {
			compatible = "mediatek,NFI";
			reg = <0x11001000 0x1000>;
			interrupts = <0x00 0x2f 0x08>;
		};

		NFIECC@0x11002000 {
			compatible = "mediatek,NFIECC";
			reg = <0x11002000 0x1000>;
			interrupts = <0x00 0x2e 0x08>;
		};

		adc_hw@11003000 {
			compatible = "mediatek,mt6735-auxadc";
			reg = <0x11003000 0x1000>;
			interrupts = <0x00 0x23 0x02>;
			linux,phandle = <0x3e>;
			phandle = <0x3e>;
		};

		FHCTL@0x11004000 {
			compatible = "mediatek,FHCTL";
			reg = <0x11004000 0x1000>;
		};

		AP_UART0@0x11005000 {
			cell-index = <0x00>;
			skip_pinmux_clk = <0x01>;
			compatible = "mediatek,AP_UART0";
			reg = <0x11005000 0x1000>;
			interrupts = <0x00 0x2c 0x08>;
		};

		AP_UART1@0x11006000 {
			cell-index = <0x01>;
			skip_pinmux_clk = <0x01>;
			compatible = "mediatek,AP_UART1";
			reg = <0x11006000 0x1000>;
			interrupts = <0x00 0x2d 0x08>;
		};

		AP_DMA_UART0_TX@0x11000480 {
			compatible = "mediatek,AP_DMA_UART0_TX";
			reg = <0x11000480 0x80>;
			interrupts = <0x00 0x38 0x08>;
		};

		AP_DMA_UART0_RX@0x11000500 {
			compatible = "mediatek,AP_DMA_UART0_RX";
			reg = <0x11000500 0x80>;
			interrupts = <0x00 0x39 0x08>;
		};

		AP_DMA_UART1_TX@0x11000580 {
			compatible = "mediatek,AP_DMA_UART1_TX";
			reg = <0x11000580 0x80>;
			interrupts = <0x00 0x3a 0x08>;
		};

		AP_DMA_UART1_RX@0x11000600 {
			compatible = "mediatek,AP_DMA_UART1_RX";
			reg = <0x11000600 0x80>;
			interrupts = <0x00 0x3b 0x08>;
		};

		pwm@11008000 {
			compatible = "mediatek,pwm";
			reg = <0x11008000 0x1000>;
			interrupts = <0x00 0x24 0x08>;
		};

		syscfg_pctl_a@0x10005000 {
			compatible = "mediatek,mt6580-pctl-a-syscfg\0syscon";
			reg = <0x10211000 0x1000>;
			linux,phandle = <0x15>;
			phandle = <0x15>;
		};

		pinctrl@0x10005000 {
			compatible = "mediatek,mt6580-pinctrl";
			reg = <0x10005000 0x1000>;
			mediatek,pctl-regmap = <0x15>;
			pins-are-numbered;
			gpio-controller;
			#gpio-cells = <0x02>;
			linux,phandle = <0x0d>;
			phandle = <0x0d>;

			msdc0@default {
				linux,phandle = <0x02>;
				phandle = <0x02>;

				pins_cmd {
					drive-strength = [02];
				};

				pins_dat {
					drive-strength = [02];
				};

				pins_clk {
					drive-strength = [02];
				};

				pins_rst {
					drive-strength = [02];
				};

				pins_ds {
					drive-strength = [02];
				};
			};

			msdc0@hs200 {
				linux,phandle = <0x03>;
				phandle = <0x03>;

				pins_cmd {
					drive-strength = [02];
				};

				pins_dat {
					drive-strength = [02];
				};

				pins_clk {
					drive-strength = [02];
				};

				pins_rst {
					drive-strength = [02];
				};

				pins_ds {
					drive-strength = [02];
				};
			};

			msdc0@register_default {
				cmd_edge = [00];
				rdata_edge = [00];
				wdata_edge = [00];
				linux,phandle = <0x04>;
				phandle = <0x04>;
			};

			mmc1_ins_default {
				linux,phandle = <0x06>;
				phandle = <0x06>;
			};

			mmc1_ins_cfg {
				linux,phandle = <0x07>;
				phandle = <0x07>;

				pins_insert {
					pins = <0x306>;
					input-schmitt-enable = <0x01>;
					slew-rate = <0x00>;
					bias-pull-up = <0x00>;
				};
			};

			msdc1@default {
				linux,phandle = <0x08>;
				phandle = <0x08>;

				pins_cmd {
					drive-strength = [03];
				};

				pins_dat {
					drive-strength = [03];
				};

				pins_clk {
					drive-strength = [03];
				};
			};

			msdc1@sdr104 {
				linux,phandle = <0x09>;
				phandle = <0x09>;

				pins_cmd {
					drive-strength = [02];
				};

				pins_dat {
					drive-strength = [02];
				};

				pins_clk {
					drive-strength = [03];
				};
			};

			msdc1@sdr50 {
				linux,phandle = <0x0a>;
				phandle = <0x0a>;

				pins_cmd {
					drive-strength = [02];
				};

				pins_dat {
					drive-strength = [02];
				};

				pins_clk {
					drive-strength = [03];
				};
			};

			msdc1@ddr50 {
				linux,phandle = <0x0b>;
				phandle = <0x0b>;

				pins_cmd {
					drive-strength = [02];
				};

				pins_dat {
					drive-strength = [02];
				};

				pins_clk {
					drive-strength = [03];
				};
			};

			msdc1@register_default {
				cmd_edge = [00];
				rdata_edge = [00];
				wdata_edge = [00];
				linux,phandle = <0x0c>;
				phandle = <0x0c>;
			};
		};

		i2c@11009000 {
			compatible = "mediatek,mt6580-i2c\0mediatek,i2c0";
			cell-index = <0x00>;
			reg = <0x11009000 0x1000>;
			interrupts = <0x00 0x28 0x08 0x00 0x32 0x08>;
			clock-div = <0x0a>;
			#address-cells = <0x01>;
			#size-cells = <0x00>;
			linux,phandle = <0x3f>;
			phandle = <0x3f>;
		};

		i2c@1100a000 {
			compatible = "mediatek,mt6580-i2c\0mediatek,i2c1";
			cell-index = <0x01>;
			reg = <0x1100a000 0x1000>;
			interrupts = <0x00 0x29 0x08 0x00 0x33 0x08>;
			clock-div = <0x0a>;
			#address-cells = <0x01>;
			#size-cells = <0x00>;
			linux,phandle = <0x40>;
			phandle = <0x40>;
		};

		i2c@1100b000 {
			compatible = "mediatek,mt6580-i2c\0mediatek,i2c2";
			cell-index = <0x02>;
			reg = <0x1100b000 0x1000>;
			interrupts = <0x00 0x2a 0x08 0x00 0x34 0x08>;
			clock-div = <0x0a>;
			#address-cells = <0x01>;
			#size-cells = <0x00>;
			linux,phandle = <0x41>;
			phandle = <0x41>;
		};

		touch@0 {
			compatible = "mediatek,touch";
			vtouch-supply = <0x16>;
			linux,phandle = <0x42>;
			phandle = <0x42>;
		};

		accdet {
			compatible = "mediatek,pmic-accdet";
			linux,phandle = <0x43>;
			phandle = <0x43>;
		};

		gse_1 {
			compatible = "mediatek, gse_1-eint";
			status = "disabled";
			linux,phandle = <0x44>;
			phandle = <0x44>;
		};

		spi@1100c000 {
			compatible = "mediatek,mt6580-spi";
			cell-index = <0x00>;
			reg = <0x1100c000 0x1000>;
			interrupts = <0x00 0x40 0x08>;
			mediatek,spi-padmacro = <0x00>;
		};

		THERM_CTRL@0x1100D000 {
			compatible = "mediatek,THERM_CTRL";
			reg = <0x1100d000 0x1000>;
			interrupts = <0x00 0x25 0x08>;
		};

		btif@1100e000 {
			compatible = "mediatek,btif";
			#address-cells = <0x02>;
			#size-cells = <0x02>;
			reg = <0x1100e000 0x1000 0x11000380 0x80 0x11000400 0x80>;
			interrupts = <0x00 0x43 0x08 0x00 0x36 0x08 0x00 0x37 0x08>;
		};

		gps {
			compatible = "mediatek,gps";
		};

		BTCVSD@0x10001000 {
			compatible = "mediatek,audio_bt_cvsd";
			offset = <0xc00 0x02 0xfd0 0xfd4 0xfd8>;
			reg = <0x10001000 0x1000 0x18000000 0x10000 0x18080000 0x8000>;
			interrupts = <0x00 0x99 0x08>;
		};

		consys@18070000 {
			compatible = "mediatek,mt6580-consys";
			reg = <0x18070000 0x200 0x10007000 0x100 0x10000000 0x2000 0x10006000 0x1000 0x10005000 0x1000>;
			interrupts = <0x00 0x9a 0x08 0x00 0x9c 0x08>;
			vcn18-supply = <0x17>;
			vcn28-supply = <0x18>;
			vcn33_bt-supply = <0x19>;
			vcn33_wifi-supply = <0x1a>;
			linux,phandle = <0x45>;
			phandle = <0x45>;
		};

		WIFI@0x180F0000 {
			compatible = "mediatek,WIFI";
			reg = <0x180f0000 0x5c>;
			interrupts = <0x00 0x9b 0x08>;
		};

		DISP_PWM@0x1100F000 {
			compatible = "mediatek,DISP_PWM";
			reg = <0x1100f000 0x1000>;
			interrupts = <0x00 0x21 0x08>;
		};

		USB0@0x11100000 {
			compatible = "mediatek,USB0";
			cell-index = <0x00>;
			reg = <0x11100000 0x10000 0x11110000 0x10000>;
			interrupts = <0x00 0x20 0x08>;
			mode = <0x02>;
			multipoint = <0x01>;
			dyn_fifo = <0x01>;
			soft_con = <0x01>;
			dma = <0x01>;
			num_eps = <0x10>;
			dma_channels = <0x08>;
			linux,phandle = <0x46>;
			phandle = <0x46>;
		};

		usbiddig {
			compatible = "mediatek,usb_iddig_eint";
			linux,phandle = <0x47>;
			phandle = <0x47>;
		};

		usbphy@0 {
			compatible = "usb-nop-xceiv";
			linux,phandle = <0x48>;
			phandle = <0x48>;
		};

		audio@11140000 {
			compatible = "mediatek,audio";
			reg = <0x11140000 0x10000>;
			interrupts = <0x00 0x50 0x08>;
		};

		mt_soc_dl1_pcm@11140000 {
			compatible = "mediatek,mt_soc_pcm_dl1";
			reg = <0x11140000 0x1000>;
			interrupts = <0x00 0x50 0x08>;
			audclk-gpio = <0x1a 0x00>;
			audmiso-gpio = <0x1c 0x00>;
			audmosi-gpio = <0x1b 0x00>;
			linux,phandle = <0x49>;
			phandle = <0x49>;
		};

		mt_soc_ul1_PCM {
			compatible = "mediatek,mt_soc_pcm_capture";
		};

		mt_soc_voice_md1 {
			compatible = "mediatek,mt_soc_pcm_voice_md1";
		};

		mt_soc_hdmi_pcm {
			compatible = "mediatek,mt_soc_pcm_hdmi";
		};

		mt_soc_uldlloopback_pcm {
			compatible = "mediatek,mt_soc_pcm_uldlloopback";
		};

		mt_soc_i2s0_pcm {
			compatible = "mediatek,mt_soc_pcm_dl1_i2s0";
		};

		mt_soc_mrgrx_pcm {
			compatible = "mediatek,mt_soc_pcm_mrgrx";
		};

		mt_soc_mrgrx_awb_pcm {
			compatible = "mediatek,mt_soc_pcm_mrgrx_awb";
		};

		mt_soc_fm_i2s_pcm {
			compatible = "mediatek,mt_soc_pcm_fm_i2s";
		};

		mt_soc_fm_i2s_awb_pcm {
			compatible = "mediatek,mt_soc_pcm_fm_i2s_awb";
		};

		mt_soc_i2s0dl1_pcm {
			compatible = "mediatek,mt_soc_pcm_dl1_i2s0Dl1";
		};

		mt_soc_deep_buffer_dl_pcm {
			compatible = "mediatek,mt_soc_pcm_deep_buffer_dl";
		};

		mt_soc_dl1_awb_pcm {
			compatible = "mediatek,mt_soc_pcm_dl1_awb";
		};

		mt_soc_voice_md1_bt {
			compatible = "mediatek,mt_soc_pcm_voice_md1_bt";
		};

		mt_soc_voip_bt_out {
			compatible = "mediatek,mt_soc_pcm_dl1_bt";
		};

		mt_soc_voip_bt_in {
			compatible = "mediatek,mt_soc_pcm_bt_dai";
		};

		mt_soc_tdmrx_pcm {
			compatible = "mediatek,mt_soc_tdm_capture";
		};

		mt_soc_fm_mrgtx_pcm {
			compatible = "mediatek,mt_soc_pcm_fmtx";
		};

		mt_soc_ul2_pcm {
			compatible = "mediatek,mt_soc_pcm_capture2";
		};

		mt_soc_i2s0_awb_pcm {
			compatible = "mediatek,mt_soc_pcm_i2s0_awb";
		};

		mt_soc_voice_md2 {
			compatible = "mediatek,mt_soc_pcm_voice_md2";
		};

		mt_soc_routing_pcm {
			compatible = "mediatek,mt_soc_pcm_routing";
		};

		mt_soc_voice_md2_bt {
			compatible = "mediatek,mt_soc_pcm_voice_md2_bt";
		};

		mt_soc_hp_impedance_pcm {
			compatible = "mediatek,Mt_soc_pcm_hp_impedance";
		};

		mt_soc_codec_name {
			compatible = "mediatek,mt_soc_codec_63xx";
		};

		mt_soc_dummy_pcm {
			compatible = "mediatek,mt_soc_pcm_dummy";
		};

		mt_soc_codec_dummy_name {
			compatible = "mediatek,mt_soc_codec_dummy";
		};

		mt_soc_routing_dai_name {
			compatible = "mediatek,mt_soc_dai_routing";
		};

		mt_soc_dai_name {
			compatible = "mediatek,mt_soc_dai_stub";
		};

		mt_soc_dl2_pcm {
			compatible = "mediatek,mt_soc_pcm_dl2";
		};

		AHB_MOM@0x11150000 {
			compatible = "mediatek,AHB_MOM";
			reg = <0x11150000 0x10000>;
		};

		MDI@0x11160000 {
			compatible = "mediatek,MDI";
			reg = <0x11160000 0x10000>;
		};

		G3D_CONFIG@0x13000000 {
			compatible = "mediatek,G3D_CONFIG";
			reg = <0x13000000 0x1000>;
		};

		MALI@0x13010000 {
			compatible = "mediatek,MALI";
			reg = <0x13010000 0x10000>;
		};

		mmsys_config@14000000 {
			compatible = "mediatek,mmsys_config";
			reg = <0x14000000 0x1000>;
			interrupts = <0x00 0x84 0x08>;
			linux,phandle = <0x1d>;
			phandle = <0x1d>;
		};

		mdp_rdma@14001000 {
			compatible = "mediatek,mdp_rdma";
			reg = <0x14001000 0x1000>;
			interrupts = <0x00 0x71 0x08>;
		};

		mdp_rsz0@14002000 {
			compatible = "mediatek,mdp_rsz0";
			reg = <0x14002000 0x1000>;
			interrupts = <0x00 0x72 0x08>;
		};

		mdp_rsz1@14003000 {
			compatible = "mediatek,mdp_rsz1";
			reg = <0x14003000 0x1000>;
			interrupts = <0x00 0x73 0x08>;
		};

		mdp_wdma@14004000 {
			compatible = "mediatek,mdp_wdma";
			reg = <0x14004000 0x1000>;
			interrupts = <0x00 0x75 0x08>;
		};

		mdp_wrot@14005000 {
			compatible = "mediatek,mdp_wrot";
			reg = <0x14005000 0x1000>;
			interrupts = <0x00 0x76 0x08>;
		};

		mdp_tdshp@14006000 {
			compatible = "mediatek,mdp_tdshp";
			reg = <0x14006000 0x1000>;
			interrupts = <0x00 0x74 0x08>;
		};

		lcm {
			compatible = "mediatek,mt6580-lcm";
			linux,phandle = <0x4a>;
			phandle = <0x4a>;
		};

		nfc {
			compatible = "mediatek,nfc-gpio-v2";
			gpio-ven = <0x0b>;
			gpio-rst = <0x0a>;
			gpio-eint = <0x0c>;
			gpio-irq = <0x09>;
			linux,phandle = <0x4b>;
			phandle = <0x4b>;
		};

		DISPSYS@0x14007000 {
			compatible = "mediatek,DISPSYS";
			reg = <0x14000000 0x1000 0x14007000 0x1000 0x14008000 0x1000 0x14009000 0x1000 0x1400a000 0x1000 0x1400b000 0x1000 0x1400c000 0x1000 0x1400d000 0x1000 0x1400e000 0x1000 0x1400f000 0x1000 0x14010000 0x1000 0x14011000 0x1000 0x14012000 0x1000 0x14013000 0x1000 0x1100f000 0x1000 0x14015000 0x1000 0x14016000 0x1000 0x14017000 0x1000 0x14018000 0x1000>;
			interrupts = <0x00 0x00 0x08 0x00 0x77 0x08 0x00 0x00 0x08 0x00 0x79 0x08 0x00 0x00 0x08 0x00 0x7b 0x08 0x00 0x7c 0x08 0x00 0x00 0x08 0x00 0x7e 0x08 0x00 0x7f 0x08 0x00 0x80 0x08 0x00 0x00 0x08 0x00 0x82 0x08 0x00 0x00 0x08 0x00 0x00 0x08 0x00 0x70 0x08 0x00 0x00 0x08 0x00 0x00 0x08 0x00 0x00 0x08>;
		};

		DISP_OVL0@0x14007000 {
			compatible = "mediatek,DISP_OVL0";
			reg = <0x14007000 0x1000>;
			interrupts = <0x00 0x77 0x08>;
		};

		DISP_OVL1@0x14008000 {
			compatible = "mediatek,DISP_OVL1";
			reg = <0x14008000 0x1000>;
		};

		DISP_RDMA0@0x14009000 {
			compatible = "mediatek,DISP_RDMA0";
			reg = <0x14009000 0x1000>;
			interrupts = <0x00 0x79 0x08>;
		};

		DISP_RDMA1@0x1400A000 {
			compatible = "mediatek,DISP_RDMA1";
			reg = <0x1400a000 0x1000>;
		};

		DISP_WDMA@0x1400B000 {
			compatible = "mediatek,DISP_WDMA";
			reg = <0x1400b000 0x1000>;
			interrupts = <0x00 0x7b 0x08>;
		};

		DISP_COLOR@0x1400C000 {
			compatible = "mediatek,DISP_COLOR";
			reg = <0x1400c000 0x1000>;
			interrupts = <0x00 0x7c 0x08>;
		};

		DISP_CCORR@0x1400D000 {
			compatible = "mediatek,DISP_CCORR";
			reg = <0x1400d000 0x1000>;
		};

		DISP_AAL@0x1400E000 {
			compatible = "mediatek,DISP_AAL";
			reg = <0x1400e000 0x1000>;
			interrupts = <0x00 0x7e 0x08>;
		};

		DISP_GAMMA@0x1400F000 {
			compatible = "mediatek,DISP_GAMMA";
			reg = <0x1400f000 0x1000>;
			interrupts = <0x00 0x7f 0x08>;
		};

		DISP_DITHER@0x14010000 {
			compatible = "mediatek,DISP_DITHER";
			reg = <0x14010000 0x1000>;
			interrupts = <0x00 0x80 0x08>;
		};

		DISP_UFOE@0x14011000 {
			compatible = "mediatek,DISP_UFOE";
			reg = <0x14011000 0x1000>;
		};

		DSI@0x14012000 {
			compatible = "mediatek,DSI";
			reg = <0x14012000 0x1000>;
		};

		DPI@0x14013000 {
			compatible = "mediatek,DPI";
			reg = <0x14013000 0x1000>;
		};

		PTP_FSM@0x1100D000 {
			compatible = "mediatek,PTP_FSM";
			reg = <0x1100d000 0x1000>;
			interrupts = <0x00 0x2b 0x08>;
		};

		MM_MUTEX@0x14015000 {
			compatible = "mediatek,MM_MUTEX";
			reg = <0x14015000 0x1000>;
			interrupts = <0x00 0x70 0x08>;
		};

		SMI_LARB0@0x14016000 {
			cell-index = <0x00>;
			compatible = "mediatek,SMI_LARB0\0mediatek,smi_larb";
			reg = <0x14016000 0x1000>;
			interrupts = <0x00 0x85 0x08>;
			linux,phandle = <0x1b>;
			phandle = <0x1b>;
		};

		SMI_COMMON@0x14017000 {
			compatible = "mediatek,SMI_COMMON\0mediatek,smi_common";
			reg = <0x14017000 0x1000>;
			nr_larbs = <0x02>;
			larbs = <0x1b 0x1c>;
			mmsys_config = <0x1d>;
		};

		MIPI_TX_CONFIG@0x14018000 {
			compatible = "mediatek,MIPI_TX_CONFIG";
			reg = <0x14018000 0x1000>;
		};

		ISPSYS@0x15000000 {
			compatible = "mediatek,ISPSYS";
			reg = <0x15004000 0x9000 0x15000000 0x10000 0x10011000 0x4000 0x10017000 0x1000>;
			interrupts = <0x00 0x8e 0x08 0x00 0x8b 0x08>;
		};

		ISP_SYSR@0x15000000 {
			compatible = "mediatek,ISP_SYSR";
		};

		ISP_PIPEM@0x15000000 {
			compatible = "mediatek,ISP_PIPEM";
		};

		kd_camera_hw1@15008000 {
			compatible = "mediatek,camera_hw";
			reg = <0x15008000 0x1000>;
			vcama-supply = <0x1e>;
			vcamd-supply = <0x1f>;
			vcamaf-supply = <0x20>;
			vcamio-supply = <0x21>;
			linux,phandle = <0x4c>;
			phandle = <0x4c>;
		};

		kd_camera_hw2@15008000 {
			compatible = "mediatek,camera_hw2";
			reg = <0x15008000 0x1000>;
			linux,phandle = <0x4d>;
			phandle = <0x4d>;
		};

		flashlight_core {
			compatible = "mediatek,flashlight_core";
			linux,phandle = <0x4e>;
			phandle = <0x4e>;
		};

		flashlights_lm3642 {
			compatible = "mediatek,flashlights_lm3642";
			decouple = <0x01>;
			linux,phandle = <0x4f>;
			phandle = <0x4f>;

			channel@1 {
				type = <0x00>;
				ct = <0x00>;
				part = <0x00>;
			};
		};

		seninf_top@15008000 {
			compatible = "mediatek,SENINF_TOP";
			reg = <0x15008000 0x1000>;
			interrupts = <0x00 0x8e 0x08>;
		};

		CAM_0@0x15004000 {
			compatible = "mediatek,CAM_0";
			reg = <0x15004000 0x1000>;
			interrupts = <0x00 0x8b 0x08>;
		};

		CAM_1@0x15005000 {
			compatible = "mediatek,CAM_1";
			reg = <0x15005000 0x1000>;
		};

		VENC@0x15009000 {
			compatible = "mediatek,VENC";
			reg = <0x15009000 0x1000>;
			interrupts = <0x00 0x8a 0x08>;
		};

		VDEC@0x1500B000 {
			compatible = "mediatek,VDEC";
			reg = <0x1500b000 0x1000>;
			interrupts = <0x00 0x89 0x08>;
		};

		SMI_LARB1@0x15001000 {
			cell-index = <0x01>;
			compatible = "mediatek,SMI_LARB1\0mediatek,smi_larb";
			reg = <0x15001000 0x1000>;
			interrupts = <0x00 0x88 0x08>;
			linux,phandle = <0x1c>;
			phandle = <0x1c>;
		};

		IMGSYS_CONFIG@0x15000000 {
			compatible = "mediatek,IMGSYS_CONFIG";
			reg = <0x15000000 0x1000>;
		};

		hwmsensor@0 {
			compatible = "mediatek,hwmsensor";
		};

		gsensor@0 {
			compatible = "mediatek,gsensor";
		};

		als_ps@0 {
			compatible = "mediatek,als_ps";
			linux,phandle = <0x50>;
			phandle = <0x50>;
		};

		m_acc_pl@0 {
			compatible = "mediatek,m_acc_pl";
		};

		m_alsps_pl@0 {
			compatible = "mediatek,m_alsps_pl";
		};

		sensorHub@0 {
			compatible = "mediatek,sensorHub";
		};

		shf@0 {
			compatible = "mediatek,shf";
		};

		m_batch_pl@0 {
			compatible = "mediatek,m_batch_pl";
		};

		gyroscope@0 {
			compatible = "mediatek,gyroscope";
			linux,phandle = <0x51>;
			phandle = <0x51>;
		};

		m_gyro_pl@0 {
			compatible = "mediatek,m_gyro_pl";
		};

		barometer@0 {
			compatible = "mediatek,barometer";
		};

		m_baro_pl@0 {
			compatible = "mediatek,m_baro_pl";
		};

		msensor@0 {
			compatible = "mediatek,msensor";
		};

		m_mag_pl@0 {
			compatible = "mediatek,m_mag_pl";
		};

		orientation@0 {
			compatible = "mediatek,orientation";
		};

		pedometer@0 {
			compatible = "mediatek,pedometer";
		};

		m_pdr_pl@0 {
			compatible = "mediatek,m_pdr_pl";
		};

		step_counter@0 {
			compatible = "mediatek,step_counter";
		};

		m_step_c_pl@0 {
			compatible = "mediatek,m_step_c_pl";
		};

		in_pocket@0 {
			compatible = "mediatek,in_pocket";
		};

		m_inpk_pl@0 {
			compatible = "mediatek,m_inpk_pl";
		};

		shake@0 {
			compatible = "mediatek,shake";
		};

		m_shk_pl@0 {
			compatible = "mediatek,m_shk_pl";
		};

		face_down@0 {
			compatible = "mediatek,face_down";
		};

		m_fdn_pl@0 {
			compatible = "mediatek,m_fdn_pl";
		};

		activity@0 {
			compatible = "mediatek,activity";
		};

		m_act_pl@0 {
			compatible = "mediatek,m_act_pl";
		};

		heart_rate@0 {
			compatible = "mediatek,heart_rate";
		};

		m_hrm_pl@0 {
			compatible = "mediatek,m_hrm_pl";
		};

		tilt_detector@0 {
			compatible = "mediatek,tilt_detector";
		};

		m_tilt_pl@0 {
			compatible = "mediatek,m_tilt_pl";
		};

		wake_gesture@0 {
			compatible = "mediatek,wake_gesture";
		};

		m_wag_pl@0 {
			compatible = "mediatek,m_wag_pl";
		};

		glance_gesture@0 {
			compatible = "mediatek,glance_gesture";
		};

		m_glg_pl@0 {
			compatible = "mediatek,m_glg_pl";
		};

		pick_up@0 {
			compatible = "mediatek,pick_up";
		};

		m_pkup_pl@0 {
			compatible = "mediatek,m_pkup_pl";
		};

		als {
			compatible = "mediatek, als-eint";
			linux,phandle = <0x52>;
			phandle = <0x52>;
		};

		mtkfb@0 {
			compatible = "mediatek,mtkfb";
			linux,phandle = <0x53>;
			phandle = <0x53>;
		};

		dsi_te {
			compatible = "mediatek, dsi_te-eint";
			linux,phandle = <0x54>;
			phandle = <0x54>;
		};
	};

	MOBICORE {
		compatible = "trustonic,mobicore";
		interrupts = <0x00 0x97 0x01>;
	};

	utos {
		compatible = "microtrust,utos";
		interrupts = <0x00 0x9f 0x01 0x00 0xa0 0x01>;
	};

	mt_pmic_regulator {
		compatible = "mediatek,mt_pmic";

		buck_regulators {
			compatible = "mediatek,mt_pmic_buck_regulators";

			buck_vpa {
				regulator-name = "vpa";
				regulator-min-microvolt = <0x7a120>;
				regulator-max-microvolt = <0x37b1d0>;
				regulator-ramp-delay = <0xc350>;
				regulator-enable-ramp-delay = <0xb4>;
				linux,phandle = <0x55>;
				phandle = <0x55>;
			};

			buck_vproc {
				regulator-name = "vproc";
				regulator-min-microvolt = <0xaae60>;
				regulator-max-microvolt = <0x16caf6>;
				regulator-ramp-delay = <0x186a>;
				regulator-enable-ramp-delay = <0xb4>;
				regulator-always-on;
				regulator-boot-on;
				linux,phandle = <0x56>;
				phandle = <0x56>;
			};
		};

		ldo_regulators {
			compatible = "mediatek,mt_pmic_ldo_regulators";

			ldo_vcn28 {
				regulator-name = "vcn28";
				regulator-min-microvolt = <0x1b7740>;
				regulator-max-microvolt = <0x2ab980>;
				regulator-enable-ramp-delay = <0x108>;
				linux,phandle = <0x18>;
				phandle = <0x18>;
			};

			ldo_vtcxo {
				regulator-name = "vtcxo";
				regulator-min-microvolt = <0x2191c0>;
				regulator-max-microvolt = <0x2191c0>;
				regulator-enable-ramp-delay = <0x6e>;
				linux,phandle = <0x22>;
				phandle = <0x22>;
			};

			ldo_va {
				regulator-name = "va";
				regulator-min-microvolt = <0x1b7740>;
				regulator-max-microvolt = <0x2625a0>;
				regulator-enable-ramp-delay = <0x6e>;
				linux,phandle = <0x23>;
				phandle = <0x23>;
			};

			ldo_vcama {
				regulator-name = "vcama";
				regulator-min-microvolt = <0x16e360>;
				regulator-max-microvolt = <0x2ab980>;
				regulator-enable-ramp-delay = <0x108>;
				linux,phandle = <0x1e>;
				phandle = <0x1e>;
			};

			ldo_vcn33_bt {
				regulator-name = "vcn33_bt";
				regulator-min-microvolt = <0x325aa0>;
				regulator-max-microvolt = <0x36ee80>;
				regulator-enable-ramp-delay = <0x108>;
				linux,phandle = <0x19>;
				phandle = <0x19>;
			};

			ldo_vcn33_wifi {
				regulator-name = "vcn33_wifi";
				regulator-min-microvolt = <0x325aa0>;
				regulator-max-microvolt = <0x36ee80>;
				regulator-enable-ramp-delay = <0x108>;
				linux,phandle = <0x1a>;
				phandle = <0x1a>;
			};

			ldo_vio28 {
				regulator-name = "vio28";
				regulator-min-microvolt = <0x2ab980>;
				regulator-max-microvolt = <0x2ab980>;
				regulator-enable-ramp-delay = <0x108>;
				regulator-boot-on;
				linux,phandle = <0x24>;
				phandle = <0x24>;
			};

			ldo_vsim1 {
				regulator-name = "vsim1";
				regulator-min-microvolt = <0x1b7740>;
				regulator-max-microvolt = <0x2dc6c0>;
				regulator-enable-ramp-delay = <0x108>;
				linux,phandle = <0x25>;
				phandle = <0x25>;
			};

			ldo_vsim2 {
				regulator-name = "vsim2";
				regulator-min-microvolt = <0x1b7740>;
				regulator-max-microvolt = <0x2dc6c0>;
				regulator-enable-ramp-delay = <0x108>;
				linux,phandle = <0x26>;
				phandle = <0x26>;
			};

			ldo_vusb {
				regulator-name = "vusb";
				regulator-min-microvolt = <0x325aa0>;
				regulator-max-microvolt = <0x325aa0>;
				regulator-enable-ramp-delay = <0x108>;
				regulator-boot-on;
				linux,phandle = <0x27>;
				phandle = <0x27>;
			};

			ldo_vgp1 {
				regulator-name = "vgp1";
				regulator-min-microvolt = <0x124f80>;
				regulator-max-microvolt = <0x325aa0>;
				regulator-enable-ramp-delay = <0x108>;
				linux,phandle = <0x16>;
				phandle = <0x16>;
			};

			ldo_vgp2 {
				regulator-name = "vgp2";
				regulator-min-microvolt = <0x124f80>;
				regulator-max-microvolt = <0x2dc6c0>;
				regulator-enable-ramp-delay = <0x108>;
				linux,phandle = <0x28>;
				phandle = <0x28>;
			};

			ldo_vemc_3v3 {
				regulator-name = "vemc_3v3";
				regulator-min-microvolt = <0x2dc6c0>;
				regulator-max-microvolt = <0x325aa0>;
				regulator-enable-ramp-delay = <0x108>;
				regulator-boot-on;
				linux,phandle = <0x05>;
				phandle = <0x05>;
			};

			ldo_vcamaf {
				regulator-name = "vcamaf";
				regulator-min-microvolt = <0x124f80>;
				regulator-max-microvolt = <0x325aa0>;
				regulator-enable-ramp-delay = <0x108>;
				linux,phandle = <0x20>;
				phandle = <0x20>;
			};

			ldo_vmc {
				regulator-name = "vmc";
				regulator-min-microvolt = <0x1b7740>;
				regulator-max-microvolt = <0x325aa0>;
				regulator-enable-ramp-delay = <0x2c>;
				linux,phandle = <0x0f>;
				phandle = <0x0f>;
			};

			ldo_vmch {
				regulator-name = "vmch";
				regulator-min-microvolt = <0x2dc6c0>;
				regulator-max-microvolt = <0x325aa0>;
				regulator-enable-ramp-delay = <0x2c>;
				linux,phandle = <0x0e>;
				phandle = <0x0e>;
			};

			ldo_vibr {
				regulator-name = "vibr";
				regulator-min-microvolt = <0x124f80>;
				regulator-max-microvolt = <0x325aa0>;
				regulator-enable-ramp-delay = <0x2c>;
				linux,phandle = <0x29>;
				phandle = <0x29>;
			};

			ldo_vrtc {
				regulator-name = "vrtc";
				regulator-min-microvolt = <0x2ab980>;
				regulator-max-microvolt = <0x2ab980>;
				regulator-enable-ramp-delay = <0x2c>;
				linux,phandle = <0x2a>;
				phandle = <0x2a>;
			};

			ldo_vm {
				regulator-name = "vm";
				regulator-min-microvolt = <0x124f80>;
				regulator-max-microvolt = <0x1b7740>;
				regulator-enable-ramp-delay = <0x108>;
				regulator-boot-on;
				linux,phandle = <0x2b>;
				phandle = <0x2b>;
			};

			ldo_vrf18 {
				regulator-name = "vrf18";
				regulator-min-microvolt = <0x1b7740>;
				regulator-max-microvolt = <0x1b7740>;
				regulator-enable-ramp-delay = <0xdc>;
				linux,phandle = <0x2c>;
				phandle = <0x2c>;
			};

			ldo_vio18 {
				regulator-name = "vio18";
				regulator-min-microvolt = <0x1b7740>;
				regulator-max-microvolt = <0x1b7740>;
				regulator-enable-ramp-delay = <0x108>;
				regulator-boot-on;
				linux,phandle = <0x2d>;
				phandle = <0x2d>;
			};

			ldo_vcamd {
				regulator-name = "vcamd";
				regulator-min-microvolt = <0x124f80>;
				regulator-max-microvolt = <0x1b7740>;
				regulator-enable-ramp-delay = <0x108>;
				linux,phandle = <0x1f>;
				phandle = <0x1f>;
			};

			ldo_vcamio {
				regulator-name = "vcamio";
				regulator-min-microvolt = <0x1b7740>;
				regulator-max-microvolt = <0x1b7740>;
				regulator-enable-ramp-delay = <0xdc>;
				linux,phandle = <0x21>;
				phandle = <0x21>;
			};

			ldo_vgp3 {
				regulator-name = "vgp3";
				regulator-min-microvolt = <0x124f80>;
				regulator-max-microvolt = <0x1b7740>;
				regulator-enable-ramp-delay = <0x108>;
				linux,phandle = <0x2e>;
				phandle = <0x2e>;
			};

			ldo_vcn_1v8 {
				regulator-name = "vcn_1v8";
				regulator-min-microvolt = <0x1b7740>;
				regulator-max-microvolt = <0x1b7740>;
				regulator-enable-ramp-delay = <0x2c>;
				linux,phandle = <0x17>;
				phandle = <0x17>;
			};

			vcanio_ldo_reg {
				linux,phandle = <0x57>;
				phandle = <0x57>;
			};

			vcn33_ldo_reg {
				linux,phandle = <0x58>;
				phandle = <0x58>;
			};
		};

		regulators_supply {
			compatible = "mediatek,mt_pmic_regulator_supply";
			vcn28-supply = <0x18>;
			vtcxo-supply = <0x22>;
			va-supply = <0x23>;
			vcn33_bt-supply = <0x19>;
			vcn33_wifi-supply = <0x1a>;
			vio28-supply = <0x24>;
			vsim1-supply = <0x25>;
			vsim2-supply = <0x26>;
			vusb-supply = <0x27>;
			vgp1-supply = <0x16>;
			vgp2-supply = <0x28>;
			vemc_3v3-supply = <0x05>;
			vcamaf-supply = <0x20>;
			vmc-supply = <0x0f>;
			vmch-supply = <0x0e>;
			vibr-supply = <0x29>;
			vrtc-supply = <0x2a>;
			vm-supply = <0x2b>;
			vrf18-supply = <0x2c>;
			vio18-supply = <0x2d>;
			vcamd-supply = <0x1f>;
			vcamio-supply = <0x21>;
			vgp3-supply = <0x2e>;
			vcn_1v8-supply = <0x17>;
		};
	};

	rf_clock_buffer {
		compatible = "mediatek,rf_clock_buffer";
		#mediatek,clkbuf-quantity = <0x04>;
		#mediatek,clkbuf-config = <0x02 0x01 0x01 0x01>;
		linux,phandle = <0x59>;
		phandle = <0x59>;
	};

	firmware {

		android {
			compatible = "android,firmware";

			vbmeta {
				compatible = "android,vbmeta";
				parts = "vbmeta,boot,system,vendor,recovery";
			};

			fstab {
				compatible = "android,fstab";

				vendor {
					compatible = "android,vendor";
					dev = "/dev/block/platform/bootdevice/by-name/vendor";
					type = "ext4";
					mnt_flags = "ro";
					fsmgr_flags = "wait,avb";
				};
			};
		};
	};

	odm {
		compatible = "simple-bus";
		linux,phandle = <0x5a>;
		phandle = <0x5a>;
	};

	trusty {
		compatible = "android,trusty-smc-v1";
		ranges;
		#address-cells = <0x02>;
		#size-cells = <0x02>;

		irq {
			compatible = "android,trusty-irq-v1";
			ppi-interrupt-parent = <0x01>;
		};

		log {
			compatible = "android,trusty-log-v1";
		};

		virtio {
			compatible = "android,trusty-virtio-v1";
		};

		mtee {
			compatible = "mediatek,trusty-mtee-v1";
		};
	};

	__symbols__ {
		chosen = "/chosen";
		msdc0 = "/msdc@11120000";
		msdc1 = "/msdc@11130000";
		msdc1_ins = "/msdc1_ins@0";
		cpu0 = "/cpus/cpu@0";
		cpu1 = "/cpus/cpu@1";
		cpu2 = "/cpus/cpu@2";
		cpu3 = "/cpus/cpu@3";
		reserved_memory = "/reserved-memory";
		gic = "/interrupt-controller@10210000";
		bus = "/bus";
		bat_comm = "/bus/bat_comm";
		keypad = "/bus/keypad@10002000";
		gpio_usage_mapping = "/bus/gpio";
		gpio = "/bus/gpio@0x10005000";
		cpu_dbgapb = "/bus/cpu_dbgapb@10170000";
		eintc = "/bus/eintc@1000b000";
		ap_ccif0 = "/bus/ap_ccif0@1000C000";
		mcucfg = "/bus/mcucfg@10200000";
		sys_cirq = "/bus/sys_cirq@10202000";
		ap_dma = "/bus/dma@0x11000000";
		auxadc = "/bus/adc_hw@11003000";
		syscfg_pctl_a = "/bus/syscfg_pctl_a@0x10005000";
		pio = "/bus/pinctrl@0x10005000";
		msdc0_pins_default = "/bus/pinctrl@0x10005000/msdc0@default";
		msdc0_pins_hs200 = "/bus/pinctrl@0x10005000/msdc0@hs200";
		msdc0_register_setting_default = "/bus/pinctrl@0x10005000/msdc0@register_default";
		mmc1_pins_insert_default = "/bus/pinctrl@0x10005000/mmc1_ins_default";
		mmc1_pins_insert_cfg = "/bus/pinctrl@0x10005000/mmc1_ins_cfg";
		msdc1_pins_default = "/bus/pinctrl@0x10005000/msdc1@default";
		msdc1_pins_sdr104 = "/bus/pinctrl@0x10005000/msdc1@sdr104";
		msdc1_pins_sdr50 = "/bus/pinctrl@0x10005000/msdc1@sdr50";
		msdc1_pins_ddr50 = "/bus/pinctrl@0x10005000/msdc1@ddr50";
		msdc1_register_setting_default = "/bus/pinctrl@0x10005000/msdc1@register_default";
		i2c0 = "/bus/i2c@11009000";
		i2c1 = "/bus/i2c@1100a000";
		i2c2 = "/bus/i2c@1100b000";
		touch = "/bus/touch@0";
		accdet = "/bus/accdet";
		gse_1 = "/bus/gse_1";
		consys = "/bus/consys@18070000";
		usb0 = "/bus/USB0@0x11100000";
		usbiddig = "/bus/usbiddig";
		usbphy0 = "/bus/usbphy@0";
		audgpio = "/bus/mt_soc_dl1_pcm@11140000";
		mmsys_config = "/bus/mmsys_config@14000000";
		lcm = "/bus/lcm";
		nfc = "/bus/nfc";
		smi_larb0 = "/bus/SMI_LARB0@0x14016000";
		kd_camera_hw1 = "/bus/kd_camera_hw1@15008000";
		kd_camera_hw2 = "/bus/kd_camera_hw2@15008000";
		flashlight_core = "/bus/flashlight_core";
		flashlights_lm3642 = "/bus/flashlights_lm3642";
		smi_larb1 = "/bus/SMI_LARB1@0x15001000";
		alsps = "/bus/als_ps@0";
		gyro = "/bus/gyroscope@0";
		als = "/bus/als";
		mtkfb = "/bus/mtkfb@0";
		dsi_te = "/bus/dsi_te";
		mt_pmic_vpa_buck_reg = "/mt_pmic_regulator/buck_regulators/buck_vpa";
		mt_pmic_vproc_buck_reg = "/mt_pmic_regulator/buck_regulators/buck_vproc";
		mt_pmic_vcn28_ldo_reg = "/mt_pmic_regulator/ldo_regulators/ldo_vcn28";
		mt_pmic_vtcxo_ldo_reg = "/mt_pmic_regulator/ldo_regulators/ldo_vtcxo";
		mt_pmic_va_ldo_reg = "/mt_pmic_regulator/ldo_regulators/ldo_va";
		mt_pmic_vcama_ldo_reg = "/mt_pmic_regulator/ldo_regulators/ldo_vcama";
		mt_pmic_vcn33_bt_ldo_reg = "/mt_pmic_regulator/ldo_regulators/ldo_vcn33_bt";
		mt_pmic_vcn33_wifi_ldo_reg = "/mt_pmic_regulator/ldo_regulators/ldo_vcn33_wifi";
		mt_pmic_vio28_ldo_reg = "/mt_pmic_regulator/ldo_regulators/ldo_vio28";
		mt_pmic_vsim1_ldo_reg = "/mt_pmic_regulator/ldo_regulators/ldo_vsim1";
		mt_pmic_vsim2_ldo_reg = "/mt_pmic_regulator/ldo_regulators/ldo_vsim2";
		mt_pmic_vusb_ldo_reg = "/mt_pmic_regulator/ldo_regulators/ldo_vusb";
		mt_pmic_vgp1_ldo_reg = "/mt_pmic_regulator/ldo_regulators/ldo_vgp1";
		mt_pmic_vgp2_ldo_reg = "/mt_pmic_regulator/ldo_regulators/ldo_vgp2";
		mt_pmic_vemc_3v3_ldo_reg = "/mt_pmic_regulator/ldo_regulators/ldo_vemc_3v3";
		mt_pmic_vcamaf_ldo_reg = "/mt_pmic_regulator/ldo_regulators/ldo_vcamaf";
		mt_pmic_vmc_ldo_reg = "/mt_pmic_regulator/ldo_regulators/ldo_vmc";
		mt_pmic_vmch_ldo_reg = "/mt_pmic_regulator/ldo_regulators/ldo_vmch";
		mt_pmic_vibr_ldo_reg = "/mt_pmic_regulator/ldo_regulators/ldo_vibr";
		mt_pmic_vrtc_ldo_reg = "/mt_pmic_regulator/ldo_regulators/ldo_vrtc";
		mt_pmic_vm_ldo_reg = "/mt_pmic_regulator/ldo_regulators/ldo_vm";
		mt_pmic_vrf18_ldo_reg = "/mt_pmic_regulator/ldo_regulators/ldo_vrf18";
		mt_pmic_vio18_ldo_reg = "/mt_pmic_regulator/ldo_regulators/ldo_vio18";
		mt_pmic_vcamd_ldo_reg = "/mt_pmic_regulator/ldo_regulators/ldo_vcamd";
		mt_pmic_vcamio_ldo_reg = "/mt_pmic_regulator/ldo_regulators/ldo_vcamio";
		mt_pmic_vgp3_ldo_reg = "/mt_pmic_regulator/ldo_regulators/ldo_vgp3";
		mt_pmic_vcn_1v8_ldo_reg = "/mt_pmic_regulator/ldo_regulators/ldo_vcn_1v8";
		mt_pmic_vcanio_ldo_reg = "/mt_pmic_regulator/ldo_regulators/vcanio_ldo_reg";
		mt_pmic_vcn33_ldo_reg = "/mt_pmic_regulator/ldo_regulators/vcn33_ldo_reg";
		rf_clock_buffer_ctrl = "/rf_clock_buffer";
		odm = "/odm";
	};
};
